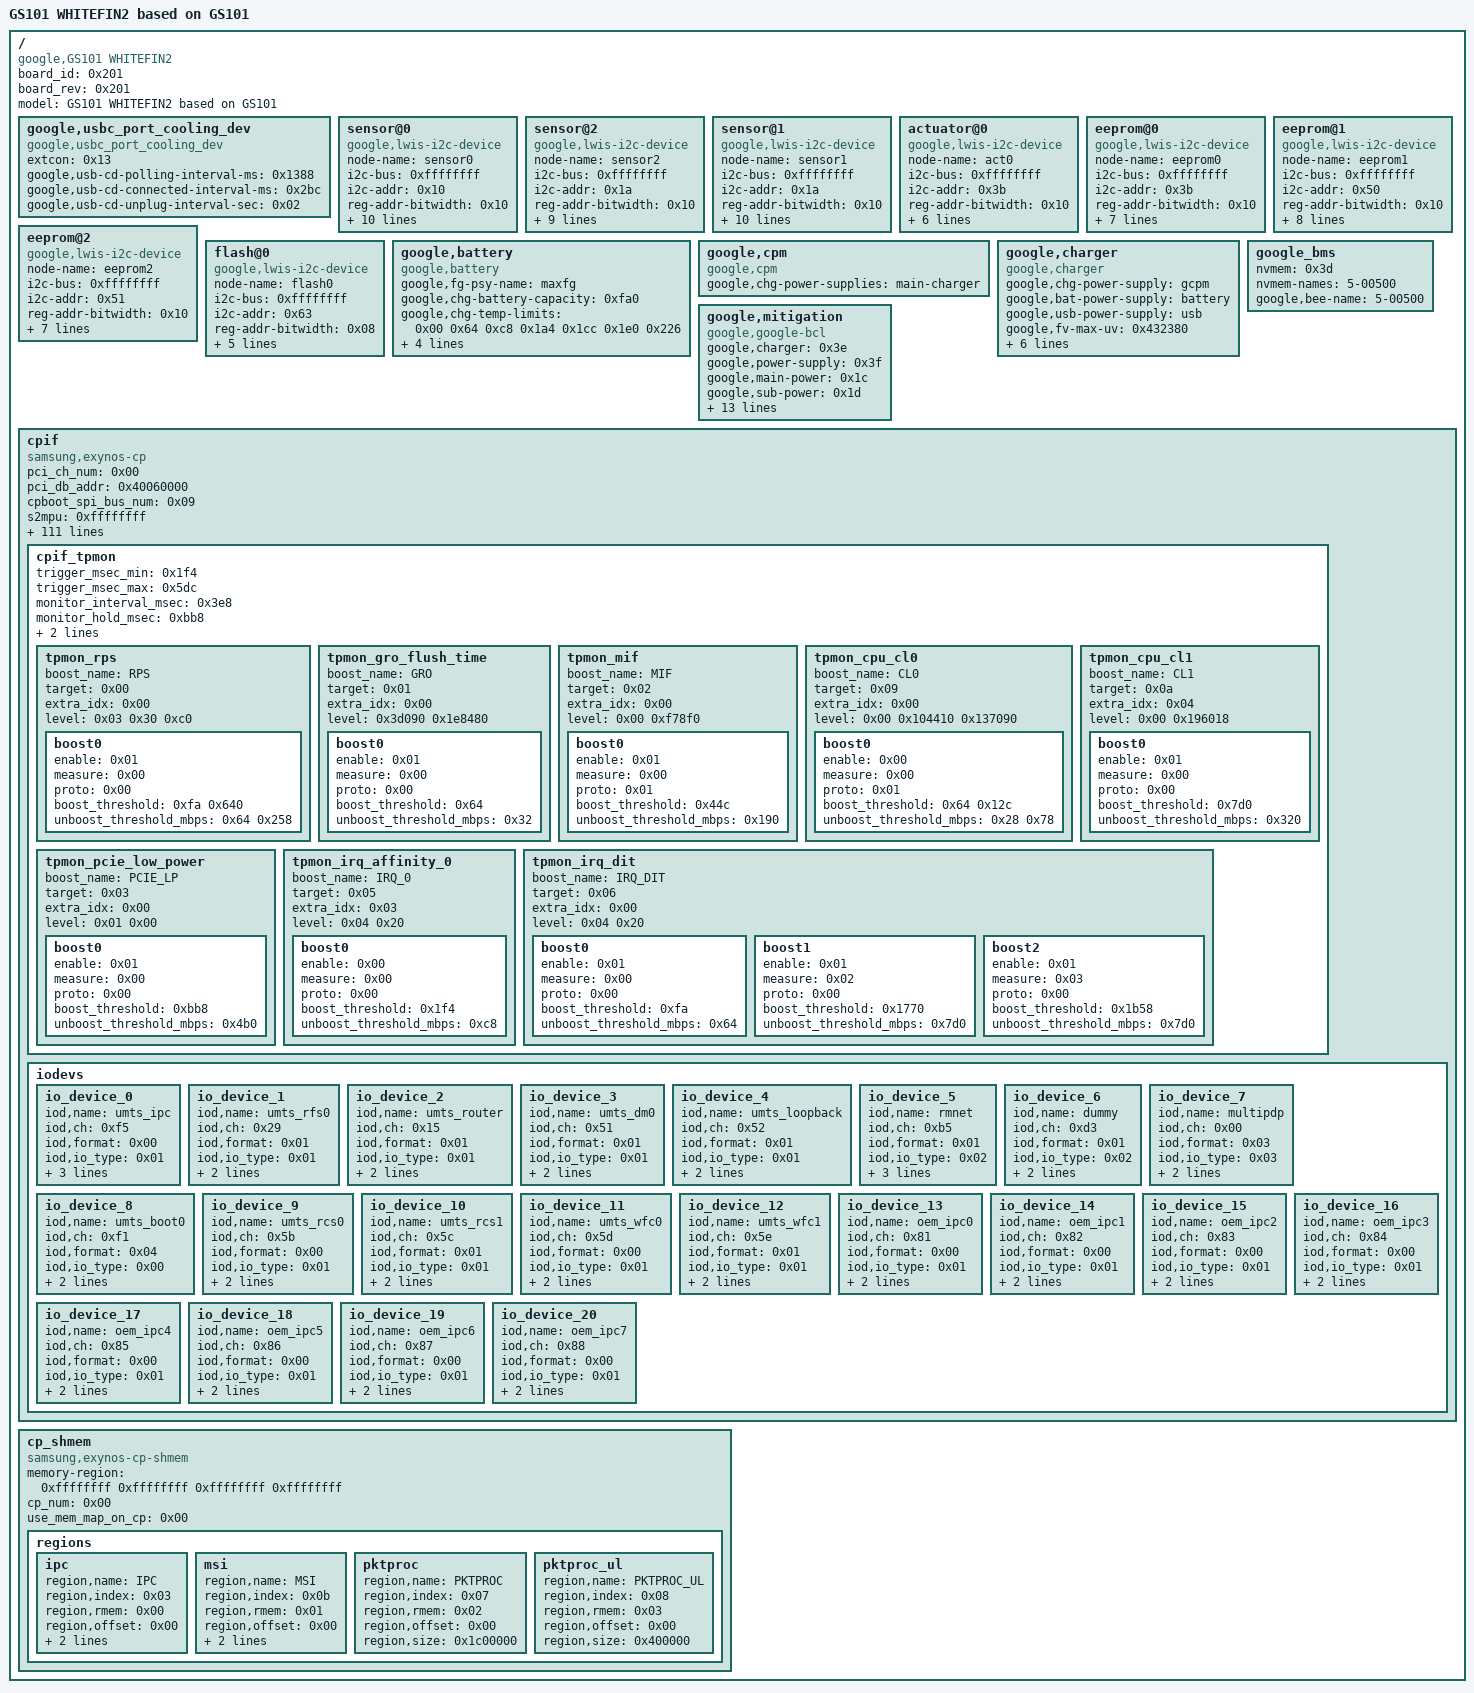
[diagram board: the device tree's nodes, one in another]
/dts-v1/;

/ {
	board_id = <0x201>;
	board_rev = <0x201>;

	fragment@0 {
		target = <0xffffffff>;

		__overlay__ {

			bt-reg-on {
				samsung,pins = "gpp16-2";
				samsung,pin-function = <0x01>;
				samsung,pin-pud = <0x00>;
				samsung,pin-drv = <0x00>;
				samsung,pin-con-pdn = <0x03>;
				samsung,pin-pud-pdn = <0x00>;
				phandle = <0x01>;
			};

			bt-dev-wake {
				samsung,pins = "gpp14-3";
				samsung,pin-function = <0x01>;
				samsung,pin-pud = <0x00>;
				samsung,pin-drv = <0x00>;
				samsung,pin-con-pdn = <0x03>;
				samsung,pin-pud-pdn = <0x01>;
				phandle = <0x02>;
			};
		};
	};

	fragment@1 {
		target = <0xffffffff>;

		__overlay__ {

			bt-host-wake {
				samsung,pins = "gpa6-6";
				samsung,pin-function = <0x0f>;
				samsung,pin-pud = <0x01>;
				samsung,pin-drv = <0x00>;
				samsung,pin-con-pdn = <0x03>;
				samsung,pin-pud-pdn = <0x01>;
				phandle = <0x03>;
			};
		};
	};

	fragment@2 {
		target = <0xffffffff>;

		__overlay__ {
			status = "okay";
		};
	};

	fragment@3 {
		target = <0xffffffff>;

		__overlay__ {

			btbcm {
				compatible = "goog,nitrous";
				pinctrl-0 = <0x01 0x02 0x03>;
				pinctrl-names = "default";
				shutdown-gpios = <0xffffffff 0x02 0x00>;
				host-wakeup-gpios = <0xffffffff 0x06 0x00>;
				device-wakeup-gpios = <0xffffffff 0x03 0x00>;
				status = "okay";
				phandle = <0x67>;
			};
		};
	};

	fragment@4 {
		target = <0xffffffff>;

		__overlay__ {
			#address-cells = <0x01>;
			#size-cells = <0x00>;
			status = "okay";
			pinctrl-names = "default";
			pinctrl-0 = <0xffffffff 0xffffffff>;
			swap-mode = <0x01>;

			bcm4775@0 {
				compatible = "ssp,bcm4775";
				reg = <0x00>;
				spi-max-frequency = <0x18cba80>;
				spi-cpol;
				spi-cpha;
				pinctrl-names = "default";
				pinctrl-0 = <0x04 0x05 0x06 0x07>;
				mcu-req-gpios = <0xffffffff 0x01 0x00>;
				nstandby-gpios = <0xffffffff 0x02 0x01>;

				controller-data {
					samsung,spi-feedback-delay = <0x01>;
					samsung,spi-chip-select-mode = <0x00>;
				};
			};
		};
	};

	fragment@5 {
		target = <0xffffffff>;

		__overlay__ {

			gps-mcu-req {
				samsung,pins = "gpp1-1";
				samsung,pin-function = <0x01>;
				samsung,pin-pud = <0x00>;
				samsung,pin-con-pdn = <0x03>;
				samsung,pin-pud-pdn = <0x00>;
				phandle = <0x05>;
			};

			gps-nstandby {
				samsung,pins = "gpp0-2";
				samsung,pin-function = <0x01>;
				samsung,pin-pud = <0x00>;
				samsung,pin-con-pdn = <0x03>;
				samsung,pin-pud-pdn = <0x00>;
				phandle = <0x07>;
			};
		};
	};

	fragment@6 {
		target = <0xffffffff>;

		__overlay__ {
			#address-cells = <0x01>;
			#size-cells = <0x00>;
			status = "okay";

			fusb307b@50 {
				status = "disabled";
				compatible = "fusb307b";
				reg = <0x50>;
				pinctrl-names = "default";
				pinctrl-0 = <0x08>;
				interrupt-parent = <0xffffffff>;
				usbpd,usbpd_int = <0xffffffff 0x02 0x01>;
				usb-psy-name = "usb";
				chg-psy-name = "gcpm";
				no-bc-12;
				ls = <0x09>;
				conn = <0x0a>;
				orientation-switch;
				phandle = <0x68>;

				connector {
					compatible = "usb-c-connector";
					label = "USB-C";
					data-role = "dual";
					power-role = "dual";
					try-power-role = "sink";
					self-powered;
					op-sink-microwatt = <0x27ac40>;
					usb-role-switch;
					source-pdos = <0x3601905a>;
					sink-pdos = <0x2601912c 0x2d0c8>;
					phandle = <0x0a>;

					port {
						#address-cells = <0x01>;
						#size-cells = <0x00>;

						endpoint@0 {
							reg = <0x00>;
							remote-endpoint = <0x0b>;
							phandle = <0x0c>;
						};
					};
				};

				port {
					#address-cells = <0x01>;
					#size-cells = <0x00>;

					endpoint@0 {
						reg = <0x00>;
						remote-endpoint = <0x0c>;
						phandle = <0x0b>;
					};
				};
			};

			slg46826@8 {
				status = "disabled";
				compatible = "slg46826";
				reg = <0x08>;
				phandle = <0x09>;
			};

			max20339ovp@35 {
				status = "okay";
				compatible = "max20339ovp";
				reg = <0x35>;
				max20339,irq-gpio = <0x0d 0x05 0x01>;
				phandle = <0x0f>;

				max20339_gpio {
					gpio-controller;
					#gpio-cells = <0x02>;
					ngpios = <0x08>;
					phandle = <0x0e>;
				};
			};

			max77759tcpc@25 {
				status = "okay";
				compatible = "max77759tcpc";
				reg = <0x25>;
				pinctrl-names = "default";
				pinctrl-0 = <0x08>;
				interrupt-parent = <0xffffffff>;
				usbpd,usbpd_int = <0xffffffff 0x02 0x01>;
				usb-psy-name = "usb";
				chg-psy-name = "gcpm";
				in-switch-gpio = <0x0e 0x04 0x00>;
				max20339,ovp = <0x0f>;
				conn = <0x10>;
				orientation-switch;
				phandle = <0x13>;

				connector {
					compatible = "usb-c-connector";
					label = "USB-C";
					data-role = "dual";
					power-role = "dual";
					try-power-role = "sink";
					self-powered;
					op-sink-microwatt = <0x27ac40>;
					new-source-frs-typec-current = <0x02>;
					usb-role-switch;
					slow-charger-loop;
					source-pdos = <0x3601905a>;
					sink-pdos = <0x3601912c 0x2d0dc 0xc0dc323c>;
					sink-vdos = <0xd14018d1 0x00 0x4ee10000 0x45800001 0x00 0x23800000>;
					sink-vdos-v1 = <0xd00018d1 0x00 0x4ee10000>;
					phandle = <0x10>;

					port {
						#address-cells = <0x01>;
						#size-cells = <0x00>;

						endpoint@0 {
							reg = <0x00>;
							remote-endpoint = <0x11>;
							phandle = <0x12>;
						};
					};
				};

				port {
					#address-cells = <0x01>;
					#size-cells = <0x00>;

					endpoint@0 {
						reg = <0x00>;
						remote-endpoint = <0x12>;
						phandle = <0x11>;
					};
				};

				max77759_tcpc_gpio {
					gpio-controller;
					#gpio-cells = <0x02>;
					ngpios = <0x01>;
					phandle = <0x57>;
				};
			};
		};
	};

	fragment@7 {
		target = <0xffffffff>;

		__overlay__ {
			samsung,pins = "gpp23-4\0gpp23-5";
			samsung,pin-pud = <0x03>;
		};
	};

	fragment@8 {
		target = <0xffffffff>;

		__overlay__ {

			usb-pd-irq {
				samsung,pins = "gpa8-2";
				samsung,pin-function = <0x0f>;
				samsung,pin-pud = <0x03>;
				samsung,pin-drv = <0x00>;
				phandle = <0x08>;
			};
		};
	};

	fragment@typec {
		target-path = "/";

		__overlay__ {

			google,usbc_port_cooling_dev {
				extcon = <0x13>;
				compatible = "google,usbc_port_cooling_dev";
				google,usb-cd-polling-interval-ms = <0x1388>;
				google,usb-cd-connected-interval-ms = <0x2bc>;
				google,usb-cd-unplug-interval-sec = <0x02>;
				#cooling-cells = <0x02>;
			};
		};
	};

	fragment@9 {
		target = <0xffffffff>;

		__overlay__ {

			cfg_wlanen {
				samsung,pins = "gpp14-2";
				samsung,pin-function = <0x01>;
				samsung,pin-pud = <0x00>;
				samsung,pin-drv = <0x00>;
				samsung,pin-con-pdn = <0x03>;
				samsung,pin-pud-pdn = <0x03>;
				phandle = <0x14>;
			};
		};
	};

	fragment@10 {
		target = <0xffffffff>;

		__overlay__ {

			wlan_host_wake {
				samsung,pins = "gpa7-0";
				samsung,pin-function = <0x0f>;
				samsung,pin-pud = <0x01>;
				samsung,pin-drv = <0x00>;
				samsung,pin-con-pdn = <0x03>;
				samsung,pin-pud-pdn = <0x01>;
				phandle = <0x15>;
			};
		};
	};

	fragment@11 {
		target = <0xffffffff>;

		__overlay__ {

			wlan_dev_wake {
				samsung,pins = "gph2-5";
				samsung,pin-function = <0x00>;
				samsung,pin-pud = <0x01>;
				samsung,pin-drv = <0x00>;
				samsung,pin-con-pdn = <0x03>;
				samsung,pin-pud-pdn = <0x01>;
				phandle = <0x16>;
			};
		};
	};

	fragment@12 {
		target = <0xffffffff>;

		__overlay__ {
			pinctrl-0 = <0xffffffff 0xffffffff 0x14 0x15 0x16>;

			wlan {
				compatible = "android,bcmdhd_wlan";
				wl_reg_on = <0xffffffff 0x02 0x01>;
				wl_host_wake = <0xffffffff 0x00 0x01>;
				wl_dev_wake = <0xffffffff 0x05 0x01>;
				ch-num = <0x01>;
				status = "okay";
			};
		};
	};

	fragment@13 {
		target = <0xffffffff>;

		__overlay__ {

			m-pmic-irq {
				samsung,pins = "gpa0-6";
				samsung,pin-pud = <0x00>;
				phandle = <0x17>;
			};

			s-pmic-irq {
				samsung,pins = "gpa0-7";
				samsung,pin-pud = <0x00>;
				phandle = <0x1a>;
			};

			smpl-warn {
				samsung,pins = "gpa5-0";
				samsung,pin-function = <0x0f>;
				samsung,pin-pud = <0x00>;
				samsung,pin-drv = <0x00>;
				phandle = <0x18>;
			};
		};
	};

	fragment@14 {
		target = <0xffffffff>;

		__overlay__ {
			#address-cells = <0x01>;
			#size-cells = <0x00>;
			status = "okay";

			s2mpg10mfd@00 {
				compatible = "samsung,s2mpg10mfd";
				acpm-ipc-channel = <0x02>;
				acpm-speedy-channel = <0x00>;
				s2mpg10,wakeup = "enabled";
				s2mpg10,irq-gpio = <0xffffffff 0x06 0x00>;
				reg = <0x1f>;
				interrupts = <0x01 0x00 0x00 0x01 0x00 0x01 0x01 0x00 0x02 0x01 0x00 0x03 0x01 0x00 0x04 0x01 0x00 0x05 0x01 0x00 0x06>;
				interrupt-parent = <0xffffffff>;
				pinctrl-names = "default";
				pinctrl-0 = <0x17 0x18>;
				gpios = <0xffffffff 0x00 0x00 0xffffffff 0x01 0x00 0xffffffff 0x02 0x00 0xffffffff 0x03 0x00 0xffffffff 0x04 0x00 0xffffffff 0x01 0x00 0xffffffff 0x03 0x00>;
				#thermal-sensor-cells = <0x01>;
				smpl_warn_en = <0x01>;
				smpl_warn_vth = <0x03>;
				smpl_warn_hys = <0x01>;
				b2_ocp_warn_en = <0x01>;
				b2_ocp_warn_cnt = <0x00>;
				b2_ocp_warn_dvs_mask = <0x00>;
				b2_ocp_warn_lvl = <0x08>;
				b3_ocp_warn_en = <0x01>;
				b3_ocp_warn_cnt = <0x00>;
				b3_ocp_warn_dvs_mask = <0x00>;
				b3_ocp_warn_lvl = <0x0d>;
				b10_ocp_warn_en = <0x01>;
				b10_ocp_warn_cnt = <0x00>;
				b10_ocp_warn_dvs_mask = <0x00>;
				b10_ocp_warn_lvl = <0x0d>;
				b2_soft_ocp_warn_en = <0x01>;
				b2_soft_ocp_warn_cnt = <0x00>;
				b2_soft_ocp_warn_dvs_mask = <0x00>;
				b2_soft_ocp_warn_lvl = <0x08>;
				b3_soft_ocp_warn_en = <0x01>;
				b3_soft_ocp_warn_cnt = <0x00>;
				b3_soft_ocp_warn_dvs_mask = <0x00>;
				b3_soft_ocp_warn_lvl = <0x0d>;
				b10_soft_ocp_warn_en = <0x01>;
				b10_soft_ocp_warn_cnt = <0x00>;
				b10_soft_ocp_warn_dvs_mask = <0x00>;
				b10_soft_ocp_warn_lvl = <0x14>;
				buck_ocp_ctrl1 = <0xbb>;
				buck_ocp_ctrl2 = <0xbb>;
				buck_ocp_ctrl3 = <0xbb>;
				buck_ocp_ctrl4 = <0xbb>;
				buck_ocp_ctrl5 = <0xbb>;
				wtsr_en = "enabled";
				coldrst_en = "disabled";
				smpl_en = "disabled";
				wtsr_timer_val = <0x03>;
				coldrst_timer_val = <0x03>;
				smpl_timer_val = <0x04>;
				sub_smpl_en = "disabled";
				check_jigon = <0x00>;
				init_time,sec = <0x00>;
				init_time,min = <0x00>;
				init_time,hour = <0x0c>;
				init_time,mday = <0x01>;
				init_time,mon = <0x00>;
				init_time,year = <0x78>;
				init_time,wday = <0x03>;
				phandle = <0x1c>;

				regulators {

					BUCK1M {
						regulator-name = "S2MPG10_BUCK1";
						regulator-min-microvolt = <0x6ddd0>;
						regulator-max-microvolt = <0x13d620>;
						regulator-always-on;
						regulator-initial-mode = <0x01>;
						channel-mux-selection = <0x01>;
						schematic-name = "S1M_VDD_MIF";
						subsys-name = "MIF";
						buck_rail;
						channel-en-byte-offset = <0x00>;
						channel-en-index = <0x01>;
						phandle = <0x69>;
					};

					BUCK2M {
						regulator-name = "S2MPG10_BUCK2";
						regulator-min-microvolt = <0x6ddd0>;
						regulator-max-microvolt = <0x13d620>;
						regulator-always-on;
						regulator-initial-mode = <0x01>;
						channel-mux-selection = <0x02>;
						schematic-name = "S2M_VDD_CPUCL2";
						subsys-name = "CPU(BIG)";
						buck_rail;
						channel-en-byte-offset = <0x00>;
						channel-en-index = <0x02>;
						odpm_disable_in_sleep;
						phandle = <0x6a>;
					};

					BUCK3M {
						regulator-name = "S2MPG10_BUCK3";
						regulator-min-microvolt = <0x6ddd0>;
						regulator-max-microvolt = <0x13d620>;
						regulator-always-on;
						regulator-initial-mode = <0x01>;
						channel-mux-selection = <0x03>;
						schematic-name = "S3M_VDD_CPUCL1";
						subsys-name = "CPU(MID)";
						buck_rail;
						channel-en-byte-offset = <0x00>;
						channel-en-index = <0x04>;
						odpm_disable_in_sleep;
						phandle = <0x6b>;
					};

					BUCK4M {
						regulator-name = "S2MPG10_BUCK4";
						regulator-min-microvolt = <0x6ddd0>;
						regulator-max-microvolt = <0x13d620>;
						regulator-always-on;
						regulator-initial-mode = <0x01>;
						channel-mux-selection = <0x04>;
						schematic-name = "S4M_VDD_CPUCL0";
						subsys-name = "CPU(LITTLE)";
						buck_rail;
						channel-en-byte-offset = <0x00>;
						channel-en-index = <0x08>;
						odpm_disable_in_sleep;
						phandle = <0x6c>;
					};

					BUCK5M {
						regulator-name = "S2MPG10_BUCK5";
						regulator-min-microvolt = <0x6ddd0>;
						regulator-max-microvolt = <0x13d620>;
						regulator-always-on;
						regulator-initial-mode = <0x01>;
						channel-mux-selection = <0x05>;
						schematic-name = "S5M_VDD_INT";
						subsys-name = "INT";
						buck_rail;
						channel-en-byte-offset = <0x00>;
						channel-en-index = <0x10>;
						odpm_disable_in_sleep;
						phandle = <0x6d>;
					};

					BUCK6M {
						regulator-name = "S2MPG10_BUCK6";
						regulator-min-microvolt = <0x6ddd0>;
						regulator-max-microvolt = <0x13d620>;
						regulator-always-on;
						regulator-initial-mode = <0x01>;
						channel-mux-selection = <0x06>;
						schematic-name = "S6M_VDD_CPUCL2_M";
						subsys-name = "CPU(BIG)";
						buck_rail;
						channel-en-byte-offset = <0x00>;
						channel-en-index = <0x20>;
						odpm_disable_in_sleep;
						phandle = <0x6e>;
					};

					BUCK7M {
						regulator-name = "S2MPG10_BUCK7";
						regulator-min-microvolt = <0x6ddd0>;
						regulator-max-microvolt = <0x13d620>;
						regulator-always-on;
						regulator-initial-mode = <0x01>;
						channel-mux-selection = <0x07>;
						schematic-name = "S7M_VDD_INT_M";
						subsys-name = "INT";
						buck_rail;
						channel-en-byte-offset = <0x00>;
						channel-en-index = <0x40>;
						odpm_disable_in_sleep;
						phandle = <0x6f>;
					};

					BUCK8M {
						regulator-name = "S2MPG10_BUCK8";
						regulator-min-microvolt = <0x6ddd0>;
						regulator-max-microvolt = <0x13d620>;
						regulator-always-on;
						regulator-initial-mode = <0x03>;
						channel-mux-selection = <0x08>;
						schematic-name = "S8M_LLDO2";
						subsys-name = "LDO";
						buck_rail;
						channel-en-byte-offset = <0x00>;
						channel-en-index = <0x80>;
						phandle = <0x70>;
					};

					BUCK9M {
						regulator-name = "S2MPG10_BUCK9";
						regulator-min-microvolt = <0x6ddd0>;
						regulator-max-microvolt = <0x13d620>;
						regulator-always-on;
						regulator-initial-mode = <0x03>;
						channel-mux-selection = <0x09>;
						schematic-name = "S9M_LLDO3";
						subsys-name = "LDO";
						buck_rail;
						channel-en-byte-offset = <0x01>;
						channel-en-index = <0x01>;
						phandle = <0x71>;
					};

					BUCK10M {
						regulator-name = "S2MPG10_BUCK10";
						regulator-min-microvolt = <0x6ddd0>;
						regulator-max-microvolt = <0x13d620>;
						regulator-always-on;
						regulator-initial-mode = <0x01>;
						channel-mux-selection = <0x0a>;
						schematic-name = "S10M_VDD_TPU";
						subsys-name = "TPU";
						buck_rail;
						channel-en-byte-offset = <0x01>;
						channel-en-index = <0x02>;
						odpm_disable_in_sleep;
						phandle = <0x72>;
					};

					LDO1M {
						regulator-name = "S2MPG10_LDO1";
						regulator-min-microvolt = <0xaae60>;
						regulator-max-microvolt = <0x13d620>;
						regulator-always-on;
						regulator-initial-mode = <0x03>;
						channel-mux-selection = <0x21>;
						schematic-name = "L1M_ALIVE";
						subsys-name = "Alive";
						phandle = <0x73>;
					};

					LDO2M {
						regulator-name = "S2MPG10_LDO2";
						regulator-min-microvolt = <0x186a00>;
						regulator-max-microvolt = <0x1dc130>;
						regulator-always-on;
						regulator-initial-mode = <0x03>;
						channel-mux-selection = <0x22>;
						schematic-name = "L2M_ALIVE";
						subsys-name = "DDR";
						phandle = <0x74>;
					};

					LDO3M {
						regulator-name = "S2MPG10_LDO3";
						regulator-min-microvolt = <0xb1008>;
						regulator-max-microvolt = <0x13d620>;
						regulator-always-on;
						regulator-initial-mode = <0x01>;
						channel-mux-selection = <0x23>;
						schematic-name = "L3M";
						subsys-name = "IO";
						phandle = <0x75>;
					};

					LDO4M {
						regulator-name = "S2MPG10_LDO4";
						regulator-min-microvolt = <0x186a00>;
						regulator-max-microvolt = <0x1dc130>;
						regulator-always-on;
						regulator-initial-mode = <0x01>;
						channel-mux-selection = <0x24>;
						schematic-name = "L4M";
						subsys-name = "IO";
						phandle = <0x76>;
					};

					LDO5M {
						regulator-name = "S2MPG10_LDO5";
						regulator-min-microvolt = <0xb1008>;
						regulator-max-microvolt = <0x13d620>;
						regulator-always-on;
						regulator-initial-mode = <0x01>;
						channel-mux-selection = <0x25>;
						schematic-name = "L5M_TCXO";
						subsys-name = "PLL";
						phandle = <0x77>;
					};

					LDO6M {
						regulator-name = "S2MPG10_LDO6";
						regulator-min-microvolt = <0xb1008>;
						regulator-max-microvolt = <0x13d620>;
						regulator-always-on;
						regulator-initial-mode = <0x01>;
						channel-mux-selection = <0x26>;
						schematic-name = "L6M_PLL";
						subsys-name = "PLL";
						phandle = <0x78>;
					};

					LDO7M {
						regulator-name = "S2MPG10_LDO7";
						regulator-min-microvolt = <0x6ddd0>;
						regulator-max-microvolt = <0xe7ef0>;
						regulator-initial-mode = <0x03>;
						channel-mux-selection = <0x27>;
						schematic-name = "L7M_VDD_HSI";
						subsys-name = "IO";
						phandle = <0x23>;
					};

					LDO8M {
						regulator-name = "S2MPG10_LDO8";
						regulator-min-microvolt = <0xb1008>;
						regulator-max-microvolt = <0x13d620>;
						regulator-initial-mode = <0x03>;
						channel-mux-selection = <0x28>;
						schematic-name = "L8M_USB";
						subsys-name = "USB";
						phandle = <0x24>;
					};

					LDO9M {
						regulator-name = "S2MPG10_LDO9";
						regulator-min-microvolt = <0x186a00>;
						regulator-max-microvolt = <0x1dc130>;
						regulator-initial-mode = <0x03>;
						channel-mux-selection = <0x29>;
						schematic-name = "L9M_USB";
						subsys-name = "USB";
						phandle = <0x25>;
					};

					LDO10M {
						regulator-name = "S2MPG10_LDO10";
						regulator-min-microvolt = <0x1b7740>;
						regulator-max-microvolt = <0x331df0>;
						regulator-initial-mode = <0x03>;
						channel-mux-selection = <0x2a>;
						schematic-name = "L10M_USB";
						subsys-name = "USB";
						phandle = <0x26>;
					};

					LDO11M {
						regulator-name = "S2MPG10_LDO11";
						regulator-min-microvolt = <0xaae60>;
						regulator-max-microvolt = <0x13d620>;
						regulator-always-on;
						regulator-initial-mode = <0x01>;
						channel-mux-selection = <0x2b>;
						schematic-name = "L11M_VDD_CPUCL1_M";
						subsys-name = "CPU(MID)";
						phandle = <0x79>;
					};

					LDO12M {
						regulator-name = "S2MPG10_LDO12";
						regulator-min-microvolt = <0xaae60>;
						regulator-max-microvolt = <0x13d620>;
						regulator-always-on;
						regulator-initial-mode = <0x01>;
						channel-mux-selection = <0x2c>;
						schematic-name = "L12M_VDD_CPUCL0_M";
						subsys-name = "CPU(LITTLE)";
						phandle = <0x7a>;
					};

					LDO13M {
						regulator-name = "S2MPG10_LDO13";
						regulator-min-microvolt = <0x6ddd0>;
						regulator-max-microvolt = <0xe7ef0>;
						regulator-always-on;
						regulator-initial-mode = <0x01>;
						channel-mux-selection = <0x2d>;
						schematic-name = "L13M_VDD_TPU_M";
						subsys-name = "TPU";
						phandle = <0x7b>;
					};

					LDO14M {
						regulator-name = "S2MPG10_LDO14";
						regulator-min-microvolt = <0x186a00>;
						regulator-max-microvolt = <0x1dc130>;
						regulator-initial-mode = <0x01>;
						regulator-always-on;
						channel-mux-selection = <0x2e>;
						schematic-name = "L14M_AVDD_TCXO";
						subsys-name = "PLL";
						phandle = <0x7c>;
					};

					LDO15M {
						regulator-name = "S2MPG10_LDO15";
						regulator-min-microvolt = <0x6ddd0>;
						regulator-max-microvolt = <0xe7ef0>;
						regulator-always-on;
						regulator-initial-mode = <0x03>;
						channel-mux-selection = <0x2f>;
						schematic-name = "L15M_VDD_SLC_M";
						subsys-name = "SLC";
						phandle = <0x7d>;
					};

					LDO16M {
						regulator-name = "S2MPG10_LDO16";
						regulator-min-microvolt = <0xb1008>;
						regulator-max-microvolt = <0x13d620>;
						regulator-always-on;
						regulator-initial-mode = <0x01>;
						channel-mux-selection = <0x30>;
						schematic-name = "L16M_PCIE0";
						subsys-name = "PCIE";
						phandle = <0x27>;
					};

					LDO17M {
						regulator-name = "S2MPG10_LDO17";
						regulator-min-microvolt = <0xb1008>;
						regulator-max-microvolt = <0x13d620>;
						regulator-always-on;
						regulator-initial-mode = <0x01>;
						channel-mux-selection = <0x31>;
						schematic-name = "L17M_PCIE1";
						subsys-name = "PCIE";
						phandle = <0x29>;
					};

					LDO18M {
						regulator-name = "S2MPG10_LDO18";
						regulator-min-microvolt = <0x186a00>;
						regulator-max-microvolt = <0x1dc130>;
						regulator-always-on;
						regulator-initial-mode = <0x01>;
						channel-mux-selection = <0x32>;
						schematic-name = "L18M_PCIE0";
						subsys-name = "PCIE";
						phandle = <0x28>;
					};

					LDO19M {
						regulator-name = "S2MPG10_LDO19";
						regulator-min-microvolt = <0x186a00>;
						regulator-max-microvolt = <0x1dc130>;
						regulator-always-on;
						regulator-initial-mode = <0x01>;
						channel-mux-selection = <0x33>;
						schematic-name = "L19M_PCIE1";
						subsys-name = "PCIE";
						phandle = <0x2a>;
					};

					LDO20M {
						regulator-name = "S2MPG10_LDO20";
						regulator-min-microvolt = <0x186a00>;
						regulator-max-microvolt = <0x1dc130>;
						regulator-always-on;
						regulator-initial-mode = <0x01>;
						channel-mux-selection = <0x34>;
						schematic-name = "L20M_DMICS";
						subsys-name = "DMIC";
						phandle = <0x7e>;
					};

					LDO21M {
						regulator-name = "S2MPG10_LDO21";
						regulator-min-microvolt = <0x2625a0>;
						regulator-max-microvolt = <0x325aa0>;
						regulator-always-on;
						regulator-initial-mode = <0x03>;
						channel-mux-selection = <0x35>;
						schematic-name = "L21M_DTLS";
						subsys-name = "DTLS";
						phandle = <0x7f>;
					};

					LDO22M {
						regulator-name = "S2MPG10_LDO22";
						regulator-min-microvolt = <0x2625a0>;
						regulator-max-microvolt = <0x325aa0>;
						regulator-initial-mode = <0x03>;
						channel-mux-selection = <0x36>;
						schematic-name = "L22M_DISP_VCI";
						subsys-name = "Display";
						phandle = <0x49>;
					};

					LDO23M {
						regulator-name = "S2MPG10_LDO23";
						regulator-min-microvolt = <0x186a00>;
						regulator-max-microvolt = <0x1dc130>;
						regulator-initial-mode = <0x03>;
						channel-mux-selection = <0x37>;
						schematic-name = "L23M_DISP_VDDI";
						subsys-name = "Display";
						regulator-always-on;
						phandle = <0x80>;
					};

					LDO24M {
						regulator-name = "S2MPG10_LDO24";
						regulator-min-microvolt = <0xb1008>;
						regulator-max-microvolt = <0x13d620>;
						channel-mux-selection = <0x38>;
						schematic-name = "L24M_UNUSED";
						subsys-name = "Spare";
						phandle = <0x81>;
					};

					LDO25M {
						regulator-name = "S2MPG10_LDO25";
						regulator-min-microvolt = <0x186a00>;
						regulator-max-microvolt = <0x1dc130>;
						regulator-initial-mode = <0x03>;
						channel-mux-selection = <0x39>;
						schematic-name = "L25M_TSP_DVDD";
						subsys-name = "Touch";
						phandle = <0x52>;
					};

					LDO26M {
						regulator-name = "S2MPG10_LDO26";
						regulator-min-microvolt = <0x2625a0>;
						regulator-max-microvolt = <0x325aa0>;
						regulator-initial-mode = <0x03>;
						channel-mux-selection = <0x3a>;
						schematic-name = "L26M_TS_AVDD";
						subsys-name = "Touch";
						phandle = <0x53>;
					};

					LDO27M {
						regulator-name = "S2MPG10_LDO27";
						regulator-min-microvolt = <0x2625a0>;
						regulator-max-microvolt = <0x325aa0>;
						regulator-initial-mode = <0x03>;
						channel-mux-selection = <0x3b>;
						schematic-name = "L27M_UDFPS_AVDD";
						subsys-name = "UDFPS";
						phandle = <0x82>;
					};

					LDO28M {
						regulator-name = "S2MPG10_LDO28";
						regulator-min-microvolt = <0xb1008>;
						regulator-max-microvolt = <0x13d620>;
						regulator-initial-mode = <0x03>;
						channel-mux-selection = <0x3c>;
						schematic-name = "L28M_DISP_VDDD";
						subsys-name = "Display";
						phandle = <0x83>;
					};

					LDO29M {
						regulator-name = "S2MPG10_LDO29";
						regulator-min-microvolt = <0x186a00>;
						regulator-max-microvolt = <0x1dc130>;
						channel-mux-selection = <0x3d>;
						schematic-name = "L29M_UNUSED";
						subsys-name = "Spare";
						phandle = <0x84>;
					};

					LDO30M {
						regulator-name = "S2MPG10_LDO30";
						regulator-min-microvolt = <0x186a00>;
						regulator-max-microvolt = <0x1dc130>;
						channel-mux-selection = <0x3e>;
						schematic-name = "L30M_DMICS";
						subsys-name = "Spare";
						regulator-always-on;
						phandle = <0x85>;
					};

					LDO31M {
						regulator-name = "S2MPG10_LDO31";
						regulator-min-microvolt = <0x186a00>;
						regulator-max-microvolt = <0x1dc130>;
						regulator-initial-mode = <0x03>;
						channel-mux-selection = <0x3f>;
						schematic-name = "L31M_DISP_VDDI";
						subsys-name = "NFC";
						regulator-always-on;
						phandle = <0x4a>;
					};
				};

				odpm {
					chip-name = "S2MPG10";
					sample-rate-uhz = <0x7735940>;
					sample-rate-external-uhz = <0x1d19574>;
					max-refresh-time-ms = <0xdbba0>;

					channels {

						channel@0 {
							rail-name = "BUCK10M";
							channel_enabled;
							phandle = <0x86>;
						};

						channel@1 {
							rail-name = "VSEN_C2";
							channel_enabled;
							phandle = <0x87>;
						};

						channel@2 {
							rail-name = "VSEN_C3";
							channel_enabled;
							phandle = <0x88>;
						};

						channel@3 {
							rail-name = "BUCK2M";
							channel_enabled;
							phandle = <0x89>;
						};

						channel@4 {
							rail-name = "BUCK3M";
							channel_enabled;
							phandle = <0x8a>;
						};

						channel@5 {
							rail-name = "BUCK4M";
							channel_enabled;
							phandle = <0x8b>;
						};

						channel@6 {
							rail-name = "BUCK5M";
							channel_enabled;
							phandle = <0x8c>;
						};

						channel@7 {
							rail-name = "BUCK1M";
							channel_enabled;
							phandle = <0x8d>;
						};
					};

					rails {
						use-regulators-as-rails;

						VSEN_C1 {
							external_rail;
							channel-en-index = <0x01>;
							channel-mux-selection = <0x5c>;
							shunt-res-uohms = <0x2710>;
							schematic-name = "VSEN_C1_NC";
							subsys-name = "Spare";
							phandle = <0x8e>;
						};

						VSEN_C2 {
							external_rail;
							channel-en-index = <0x02>;
							channel-mux-selection = <0x5d>;
							shunt-res-uohms = <0x1388>;
							schematic-name = "VSYS_PWR_MODEM";
							subsys-name = "Modem";
							phandle = <0x8f>;
						};

						VSEN_C3 {
							external_rail;
							channel-en-index = <0x04>;
							channel-mux-selection = <0x5e>;
							shunt-res-uohms = <0x1388>;
							schematic-name = "VSYS_PWR_RFFE";
							subsys-name = "Cellular";
							phandle = <0x90>;
						};
					};
				};

				s2mpg10_gpio {
					gpio-controller;
					#gpio-cells = <0x02>;
					ngpios = <0x06>;
					gpio-ranges = <0x19 0x00 0x00 0x06>;
					phandle = <0x91>;
				};

				s2mpg10_pinctrl {
					phandle = <0x19>;
				};
			};
		};
	};

	fragment@15 {
		target = <0xffffffff>;

		__overlay__ {
			#address-cells = <0x01>;
			#size-cells = <0x00>;
			status = "okay";

			s2mpg11mfd@00 {
				compatible = "samsung,s2mpg11mfd";
				acpm-ipc-channel = <0x02>;
				acpm-speedy-channel = <0x01>;
				s2mpg11,wakeup = "enabled";
				s2mpg11,irq-gpio = <0xffffffff 0x07 0x00>;
				reg = <0x2f>;
				interrupts = <0x01 0x00 0x00 0x01 0x00 0x01>;
				interrupt-parent = <0xffffffff>;
				pinctrl-names = "default";
				pinctrl-0 = <0x1a>;
				gpios = <0xffffffff 0x00 0x00 0xffffffff 0x02 0x00>;
				#thermal-sensor-cells = <0x01>;
				b2_ocp_warn_en = <0x01>;
				b2_ocp_warn_cnt = <0x00>;
				b2_ocp_warn_dvs_mask = <0x00>;
				b2_ocp_warn_lvl = <0x08>;
				b2_soft_ocp_warn_en = <0x01>;
				b2_soft_ocp_warn_cnt = <0x00>;
				b2_soft_ocp_warn_dvs_mask = <0x00>;
				b2_soft_ocp_warn_lvl = <0x08>;
				buck_ocp_ctrl1 = <0xbb>;
				buck_ocp_ctrl2 = <0xbb>;
				buck_ocp_ctrl3 = <0xbb>;
				buck_ocp_ctrl4 = <0xbb>;
				buck_ocp_ctrl5 = <0xbb>;
				buck_ocp_ctrl6 = <0xbb>;
				buck_ocp_ctrl7 = <0x0b>;
				phandle = <0x1d>;

				regulators {

					BUCK1S {
						regulator-name = "S2MPG11_BUCK1";
						regulator-min-microvolt = <0x6ddd0>;
						regulator-max-microvolt = <0x13d620>;
						regulator-always-on;
						regulator-initial-mode = <0x01>;
						channel-mux-selection = <0x01>;
						schematic-name = "S1S_VDD_CAM";
						subsys-name = "Multimedia";
						buck_rail;
						channel-en-byte-offset = <0x00>;
						channel-en-index = <0x01>;
						odpm_disable_in_sleep;
						phandle = <0x92>;
					};

					BUCK2S {
						regulator-name = "S2MPG11_BUCK2";
						regulator-min-microvolt = <0x6ddd0>;
						regulator-max-microvolt = <0x13d620>;
						regulator-always-on;
						regulator-initial-mode = <0x01>;
						channel-mux-selection = <0x02>;
						schematic-name = "S2S_VDD_G3D";
						subsys-name = "GPU";
						buck_rail;
						channel-en-byte-offset = <0x00>;
						channel-en-index = <0x02>;
						odpm_disable_in_sleep;
						phandle = <0x93>;
					};

					BUCK3S {
						regulator-name = "S2MPG11_BUCK3";
						regulator-min-microvolt = <0x6ddd0>;
						regulator-max-microvolt = <0x13d620>;
						regulator-always-on;
						regulator-initial-mode = <0x03>;
						channel-mux-selection = <0x03>;
						schematic-name = "S3S_LLDO1";
						subsys-name = "LDO";
						buck_rail;
						channel-en-byte-offset = <0x00>;
						channel-en-index = <0x04>;
						phandle = <0x94>;
					};

					BUCK4S {
						regulator-name = "S2MPG11_BUCK4";
						regulator-min-microvolt = <0x6ddd0>;
						regulator-max-microvolt = <0x13d620>;
						regulator-always-on;
						regulator-initial-mode = <0x03>;
						channel-mux-selection = <0x04>;
						schematic-name = "S4S_VDD2H_MEM";
						subsys-name = "DDR";
						buck_rail;
						channel-en-byte-offset = <0x00>;
						channel-en-index = <0x08>;
						phandle = <0x95>;
					};

					BUCK5S {
						regulator-name = "S2MPG11_BUCK5";
						regulator-min-microvolt = <0x61a80>;
						regulator-max-microvolt = <0x13d620>;
						regulator-always-on;
						regulator-initial-mode = <0x01>;
						channel-mux-selection = <0x05>;
						schematic-name = "S5S_VDDQ_MEM";
						subsys-name = "DDR";
						buck_rail;
						channel-en-byte-offset = <0x00>;
						channel-en-index = <0x10>;
						phandle = <0x96>;
					};

					BUCK6S {
						regulator-name = "S2MPG11_BUCK6";
						regulator-min-microvolt = <0xf4240>;
						regulator-max-microvolt = <0x16e360>;
						regulator-always-on;
						regulator-initial-mode = <0x03>;
						channel-mux-selection = <0x06>;
						schematic-name = "S6S_LLDO4";
						subsys-name = "LDO";
						buck_rail;
						channel-en-byte-offset = <0x00>;
						channel-en-index = <0x20>;
						phandle = <0x97>;
					};

					BUCK7S {
						regulator-name = "S2MPG11_BUCK7";
						regulator-min-microvolt = <0x16e360>;
						regulator-max-microvolt = <0x2191c0>;
						regulator-always-on;
						regulator-initial-mode = <0x03>;
						channel-mux-selection = <0x07>;
						schematic-name = "S7S_MLDO";
						subsys-name = "LDO";
						buck_rail;
						channel-en-byte-offset = <0x00>;
						channel-en-index = <0x40>;
						phandle = <0x98>;
					};

					BUCK8S {
						regulator-name = "S2MPG11_BUCK8";
						regulator-min-microvolt = <0x6ddd0>;
						regulator-max-microvolt = <0x13d620>;
						regulator-always-on;
						regulator-initial-mode = <0x01>;
						channel-mux-selection = <0x08>;
						schematic-name = "S8S_VDD_G3D_L2";
						subsys-name = "GPU";
						buck_rail;
						channel-en-byte-offset = <0x00>;
						channel-en-index = <0x80>;
						odpm_disable_in_sleep;
						phandle = <0x99>;
					};

					BUCK9S {
						regulator-name = "S2MPG11_BUCK9";
						regulator-min-microvolt = <0x6ddd0>;
						regulator-max-microvolt = <0x13d620>;
						regulator-always-on;
						regulator-initial-mode = <0x03>;
						channel-mux-selection = <0x09>;
						schematic-name = "S9S_VDD_AOC";
						subsys-name = "AOC";
						buck_rail;
						channel-en-byte-offset = <0x01>;
						channel-en-index = <0x01>;
						phandle = <0x9a>;
					};

					BUCK10S {
						regulator-name = "S2MPG11_BUCK10";
						regulator-min-microvolt = <0x6ddd0>;
						regulator-max-microvolt = <0x13d620>;
						regulator-always-on;
						regulator-initial-mode = <0x03>;
						channel-mux-selection = <0x0a>;
						schematic-name = "S10S_VDD2L";
						subsys-name = "DDR";
						buck_rail;
						channel-en-byte-offset = <0x01>;
						channel-en-index = <0x02>;
						phandle = <0x9b>;
					};

					BUCKD {
						regulator-name = "S2MPG11_BUCKD";
						regulator-min-microvolt = <0x249f00>;
						regulator-max-microvolt = <0x325aa0>;
						regulator-always-on;
						regulator-initial-mode = <0x01>;
						channel-mux-selection = <0x0b>;
						schematic-name = "SD";
						subsys-name = "UFS";
						buck_rail;
						channel-en-byte-offset = <0x01>;
						channel-en-index = <0x04>;
						odpm_disable_in_sleep;
						phandle = <0x9c>;
					};

					BUCKA {
						regulator-name = "S2MPG11_BUCKA";
						regulator-min-microvolt = <0x19f0a0>;
						regulator-max-microvolt = <0x200b20>;
						regulator-always-on;
						regulator-initial-mode = <0x03>;
						channel-mux-selection = <0x0c>;
						schematic-name = "SA";
						subsys-name = "IO";
						buck_rail;
						channel-en-byte-offset = <0x01>;
						channel-en-index = <0x08>;
						phandle = <0x64>;
					};

					BUCKBOOST {
						regulator-name = "S2MPG11_BUCKBOOST";
						regulator-min-microvolt = <0x2dc6c0>;
						regulator-max-microvolt = <0x36ee80>;
						regulator-always-on;
						regulator-initial-mode = <0x03>;
						channel-mux-selection = <0x0d>;
						schematic-name = "BB_HLDO";
						subsys-name = "LDO";
						buck_rail;
						channel-en-byte-offset = <0x01>;
						channel-en-index = <0x10>;
						phandle = <0x9d>;
					};

					LDO1S {
						regulator-name = "S2MPG11_LDO1";
						regulator-min-microvolt = <0x6ddd0>;
						regulator-max-microvolt = <0xe7ef0>;
						regulator-always-on;
						regulator-initial-mode = <0x01>;
						channel-mux-selection = <0x21>;
						schematic-name = "L1S_VDD_G3D_M";
						subsys-name = "GPU";
						phandle = <0x9e>;
					};

					LDO2S {
						regulator-name = "S2MPG11_LDO2";
						regulator-min-microvolt = <0x6ddd0>;
						regulator-max-microvolt = <0xe7ef0>;
						regulator-always-on;
						regulator-initial-mode = <0x01>;
						channel-mux-selection = <0x22>;
						schematic-name = "L2S_VDD_AOC_RET";
						subsys-name = "AOC";
						phandle = <0x9f>;
					};

					LDO3S {
						regulator-name = "S2MPG11_LDO3";
						regulator-min-microvolt = <0x186a00>;
						regulator-max-microvolt = <0x1dc130>;
						channel-mux-selection = <0x23>;
						schematic-name = "L3S_UNUSED";
						subsys-name = "Spare";
						phandle = <0xa0>;
					};

					LDO4S {
						regulator-name = "S2MPG11_LDO4";
						regulator-min-microvolt = <0x2625a0>;
						regulator-max-microvolt = <0x325aa0>;
						regulator-initial-mode = <0x03>;
						channel-mux-selection = <0x24>;
						schematic-name = "L4S_UWB";
						subsys-name = "UWB";
						regulator-always-on;
						phandle = <0xa1>;
					};

					LDO5S {
						regulator-name = "S2MPG11_LDO5";
						regulator-min-microvolt = <0x186a00>;
						regulator-max-microvolt = <0x1dc130>;
						channel-mux-selection = <0x25>;
						schematic-name = "L5S_UNUSED";
						subsys-name = "Spare";
						phandle = <0xa2>;
					};

					LDO6S {
						regulator-name = "S2MPG11_LDO6";
						regulator-min-microvolt = <0x2625a0>;
						regulator-max-microvolt = <0x325aa0>;
						regulator-boot-on;
						regulator-initial-mode = <0x03>;
						channel-mux-selection = <0x26>;
						schematic-name = "L6S_PROX";
						subsys-name = "Sensors";
						phandle = <0x2c>;
					};

					LDO7S {
						regulator-name = "S2MPG11_LDO7";
						regulator-min-microvolt = <0x186a00>;
						regulator-max-microvolt = <0x1dc130>;
						regulator-boot-on;
						regulator-initial-mode = <0x03>;
						channel-mux-selection = <0x27>;
						schematic-name = "L7S_SENSORS";
						subsys-name = "Sensors";
						phandle = <0x2b>;
					};

					LDO8S {
						regulator-name = "S2MPG11_LDO8";
						regulator-min-microvolt = <0x113578>;
						regulator-max-microvolt = <0x138288>;
						regulator-always-on;
						regulator-initial-mode = <0x01>;
						channel-mux-selection = <0x28>;
						schematic-name = "L8S_UFS_VCCQ";
						subsys-name = "UFS";
						phandle = <0xa3>;
					};

					LDO9S {
						regulator-name = "S2MPG11_LDO9";
						regulator-min-microvolt = <0xb1008>;
						regulator-max-microvolt = <0x13d620>;
						regulator-always-on;
						regulator-initial-mode = <0x03>;
						channel-mux-selection = <0x29>;
						schematic-name = "L9S_GNSS_CORE";
						subsys-name = "GPS";
						phandle = <0xa4>;
					};

					LDO10S {
						regulator-name = "S2MPG11_LDO10";
						regulator-min-microvolt = <0x186a00>;
						regulator-max-microvolt = <0x1dc130>;
						regulator-always-on;
						regulator-initial-mode = <0x03>;
						channel-mux-selection = <0x2a>;
						schematic-name = "L10S_GNSS_RF";
						subsys-name = "GPS";
						phandle = <0xa5>;
					};

					LDO11S {
						regulator-name = "S2MPG11_LDO11";
						regulator-min-microvolt = <0x186a00>;
						regulator-max-microvolt = <0x1dc130>;
						regulator-always-on;
						regulator-initial-mode = <0x03>;
						channel-mux-selection = <0x2b>;
						schematic-name = "L11S_GNSS_AUX";
						subsys-name = "GPS";
						phandle = <0xa6>;
					};

					LDO12S {
						regulator-name = "S2MPG11_LDO12";
						regulator-min-microvolt = <0x186a00>;
						regulator-max-microvolt = <0x1dc130>;
						channel-mux-selection = <0x2c>;
						schematic-name = "L12S_UNUSED";
						subsys-name = "Spare";
						phandle = <0xa7>;
					};

					LDO13S {
						regulator-name = "S2MPG11_LDO13";
						regulator-min-microvolt = <0x1b7740>;
						regulator-max-microvolt = <0x331df0>;
						regulator-always-on;
						regulator-initial-mode = <0x01>;
						channel-mux-selection = <0x2d>;
						schematic-name = "L13S_DPAUX";
						subsys-name = "Display";
						phandle = <0xa8>;
					};

					LDO14S {
						regulator-name = "S2MPG11_LDO14";
						regulator-min-microvolt = <0x186a00>;
						regulator-max-microvolt = <0x1dc130>;
						regulator-initial-mode = <0x03>;
						channel-mux-selection = <0x2e>;
						schematic-name = "L14S_UWB";
						subsys-name = "UWB";
						phandle = <0xa9>;
					};

					LDO15S {
						regulator-name = "S2MPG11_LDO15";
						regulator-min-microvolt = <0x186a00>;
						regulator-max-microvolt = <0x1dc130>;
						channel-mux-selection = <0x2f>;
						schematic-name = "L15S_UNUSED";
						subsys-name = "Spare";
						phandle = <0xaa>;
					};
				};

				odpm {
					chip-name = "S2MPG11";
					sample-rate-uhz = <0x7735940>;
					sample-rate-external-uhz = <0x1d19574>;
					max-refresh-time-ms = <0xdbba0>;

					channels {

						channel@0 {
							rail-name = "VSEN_C6";
							channel_enabled;
							phandle = <0xab>;
						};

						channel@1 {
							rail-name = "LDO2S";
							channel_enabled;
							phandle = <0xac>;
						};

						channel@2 {
							rail-name = "BUCK9S";
							channel_enabled;
							phandle = <0xad>;
						};

						channel@3 {
							rail-name = "BUCK5S";
							channel_enabled;
							phandle = <0xae>;
						};

						channel@4 {
							rail-name = "BUCK10S";
							channel_enabled;
							phandle = <0xaf>;
						};

						channel@5 {
							rail-name = "BUCK4S";
							channel_enabled;
							phandle = <0xb0>;
						};

						channel@6 {
							rail-name = "BUCK2S";
							channel_enabled;
							phandle = <0xb1>;
						};

						channel@7 {
							rail-name = "VSEN_C4";
							channel_enabled;
							phandle = <0xb2>;
						};
					};

					rails {
						use-regulators-as-rails;

						VSEN_C4 {
							external_rail;
							channel-en-index = <0x01>;
							channel-mux-selection = <0x5c>;
							shunt-res-uohms = <0x2710>;
							schematic-name = "VSYS_PWR_DISPLAY";
							subsys-name = "Display";
							phandle = <0xb3>;
						};

						VSEN_C5 {
							external_rail;
							channel-en-index = <0x02>;
							channel-mux-selection = <0x5d>;
							shunt-res-uohms = <0x2710>;
							schematic-name = "VSEN_C5_NC";
							subsys-name = "Spare";
							phandle = <0xb4>;
						};

						VSEN_C6 {
							external_rail;
							channel-en-index = <0x04>;
							channel-mux-selection = <0x5e>;
							shunt-res-uohms = <0x2710>;
							schematic-name = "VSYS_PWR_MMWAVE";
							subsys-name = "Cellular";
							phandle = <0xb5>;
						};
					};
				};

				s2mpg11_gpio {
					gpio-controller;
					#gpio-cells = <0x02>;
					ngpios = <0x06>;
					gpio-ranges = <0x1b 0x00 0x00 0x06>;
					phandle = <0x2d>;
				};

				s2mpg11_pinctrl {
					phandle = <0x1b>;
				};
			};
		};
	};

	fragment@16 {
		target = <0xffffffff>;

		__overlay__ {
			main-pmic = <0x1c>;
			sub-pmic = <0x1d>;
			acpm-ipc-channel = <0x02>;
		};
	};

	fragment@17 {
		target = <0xffffffff>;

		__overlay__ {
			status = "okay";
		};
	};

	fragment@18 {
		target = <0xffffffff>;

		__overlay__ {

			key-voldown {
				samsung,pins = "gpa7-3";
				samsung,pin-function = <0x0f>;
				samsung,pin-pud = <0x00>;
				samsung,pin-drv = <0x00>;
				phandle = <0x1e>;
			};

			key-volup {
				samsung,pins = "gpa8-1";
				samsung,pin-function = <0x0f>;
				samsung,pin-pud = <0x00>;
				samsung,pin-drv = <0x00>;
				phandle = <0x1f>;
			};
		};
	};

	fragment@19 {
		target = <0xffffffff>;

		__overlay__ {

			key-power {
				samsung,pins = "gpa10-1";
				samsung,pin-function = <0x0f>;
				samsung,pin-pud = <0x00>;
				samsung,pin-drv = <0x00>;
				phandle = <0x20>;
			};
		};
	};

	fragment@20 {
		target = <0xffffffff>;

		__overlay__ {
			status = "okay";
			pinctrl-names = "default";
			pinctrl-0 = <0x1e 0x1f 0x20>;

			button@1 {
				label = "gpio-keys: KEY_VOLUMEDOWN";
				linux,code = <0x72>;
				gpios = <0xffffffff 0x03 0x0f>;
				wakeup-source;
			};

			button@2 {
				label = "gpio-keys: KEY_VOLUMEUP";
				linux,code = <0x73>;
				gpios = <0xffffffff 0x01 0x0f>;
				wakeup-source;
			};

			button@3 {
				label = "gpio-keys: KEY_POWER";
				linux,code = <0x74>;
				gpios = <0xffffffff 0x01 0x0f>;
				wakeup-source;
			};
		};
	};

	fragment@21 {
		target = <0xffffffff>;

		__overlay__ {
			usb3-lpm-capable;
			adj-sof-accuracy = <0x01>;
			samsung,no-extra-delay;
			usb_host_device_timeout = <0x7ff>;
			extcon = <0x13>;
			u1u2_exitfail_quirk;
			ux_exit_in_px_quirk;
			elastic_buf_mode_quirk;
			xhci_l2_support = <0x01>;

			dwc3 {
				dr_mode = "peripheral";
				maximum-speed = "super-speed-plus";
				usb3-lpm-capable;
				usb-psy-name = "usb";
				snps,quirk-frame-length-adjustment = <0x20>;
				snps,usb3_lpm_capable;
				snps,has-lpm-erratum;
				snps,lpm-nyet-threshold = <0x00>;
				snps,usb2-gadget-lpm-disable;
				snps,dis-u2-freeclk-exists-quirk;
				snps,dis-u1-entry-quirk;
				snps,dis-u2-entry-quirk;
				xhci_l2_support = <0x01>;
				phandle = <0xb6>;
			};
		};
	};

	fragment@22 {
		target = <0xffffffff>;

		__overlay__ {

			hs_tune {
				status = "disabled";
				hs_tune_cnt = <0x06>;
				phandle = <0x21>;

				hs_tune1 {
					tune_name = "tx_pre_emp";
					tune_value = <0x03 0x03>;
				};

				hs_tune2 {
					tune_name = "tx_vref";
					tune_value = <0x0f 0x0f>;
				};

				hs_tune3 {
					tune_name = "rx_sqrx";
					tune_value = <0x05 0x05>;
				};

				hs_tune4 {
					tune_name = "utmi_clk";
					tune_value = <0x01 0x01>;
				};

				hs_tune5 {
					tune_name = "compdis";
					tune_value = <0x07 0x07>;
				};

				hs_tune6 {
					tune_name = "tx_res";
					tune_value = <0x03 0x03>;
				};
			};

			ss_tune {
				status = "disabled";
				ss_tune_cnt = <0x24>;
				phandle = <0x22>;

				ss_tune1 {
					tune_name = "ssrx_sqhs_th_ss";
					tune_value = <0xffffffff 0xffffffff>;
				};

				ss_tune2 {
					tune_name = "ssrx_sqhs_th_ssp";
					tune_value = <0xffffffff 0xffffffff>;
				};

				ss_tune3 {
					tune_name = "ssrx_lfps_th";
					tune_value = <0xffffffff 0xffffffff>;
				};

				ss_tune4 {
					tune_name = "ssrx_adap_coef_sel";
					tune_value = <0xffffffff 0xffffffff>;
				};

				ss_tune5 {
					tune_name = "ssrx_mf_eq_psel_ctrl_ss";
					tune_value = <0xffffffff 0xffffffff>;
				};

				ss_tune6 {
					tune_name = "ssrx_mf_eq_psel_ctrl_ssp";
					tune_value = <0xffffffff 0xffffffff>;
				};

				ss_tune7 {
					tune_name = "ssrx_mf_eq_zsel_ctrl_ss";
					tune_value = <0xffffffff 0xffffffff>;
				};

				ss_tune8 {
					tune_name = "ssrx_mf_eq_zsel_ctrl_ssp";
					tune_value = <0xffffffff 0xffffffff>;
				};

				ss_tune9 {
					tune_name = "ssrx_hf_eq_rsel_ctrl_ss";
					tune_value = <0xffffffff 0xffffffff>;
				};

				ss_tune10 {
					tune_name = "ssrx_hf_eq_rsel_ctrl_ssp";
					tune_value = <0xffffffff 0xffffffff>;
				};

				ss_tune11 {
					tune_name = "ssrx_hf_eq_csel_ctrl_ss";
					tune_value = <0xffffffff 0xffffffff>;
				};

				ss_tune12 {
					tune_name = "ssrx_hf_eq_csel_ctrl_ssp";
					tune_value = <0xffffffff 0xffffffff>;
				};

				ss_tune13 {
					tune_name = "ssrx_dfe_1tap_ctrl_ss";
					tune_value = <0xffffffff 0xffffffff>;
				};

				ss_tune14 {
					tune_name = "ssrx_dfe_1tap_ctrl_ssp";
					tune_value = <0xffffffff 0xffffffff>;
				};

				ss_tune15 {
					tune_name = "ssrx_dfe_2tap_ctrl_ss";
					tune_value = <0xffffffff 0xffffffff>;
				};

				ss_tune16 {
					tune_name = "ssrx_dfe_2tap_ctrl_ssp";
					tune_value = <0xffffffff 0xffffffff>;
				};

				ss_tune17 {
					tune_name = "ssrx_dfe_3tap_ctrl_ss";
					tune_value = <0xffffffff 0xffffffff>;
				};

				ss_tune18 {
					tune_name = "ssrx_dfe_3tap_ctrl_ssp";
					tune_value = <0xffffffff 0xffffffff>;
				};

				ss_tune19 {
					tune_name = "ssrx_dfe_4tap_ctrl_ss";
					tune_value = <0xffffffff 0xffffffff>;
				};

				ss_tune20 {
					tune_name = "ssrx_dfe_4tap_ctrl_ssp";
					tune_value = <0xffffffff 0xffffffff>;
				};

				ss_tune21 {
					tune_name = "ssrx_dfe_5tap_ctrl_ss";
					tune_value = <0xffffffff 0xffffffff>;
				};

				ss_tune22 {
					tune_name = "ssrx_dfe_5tap_ctrl_ssp";
					tune_value = <0xffffffff 0xffffffff>;
				};

				ss_tune23 {
					tune_name = "ssrx_term_cal";
					tune_value = <0xffffffff 0xffffffff>;
				};

				ss_tune24 {
					tune_name = "sstx_amp_ss";
					tune_value = <0xffffffff 0xffffffff>;
				};

				ss_tune25 {
					tune_name = "sstx_deemp_ss";
					tune_value = <0xffffffff 0xffffffff>;
				};

				ss_tune26 {
					tune_name = "sstx_pre_shoot_ss";
					tune_value = <0xffffffff 0xffffffff>;
				};

				ss_tune27 {
					tune_name = "sstx_amp_ssp";
					tune_value = <0xffffffff 0xffffffff>;
				};

				ss_tune28 {
					tune_name = "sstx_deemp_ssp";
					tune_value = <0xffffffff 0xffffffff>;
				};

				ss_tune29 {
					tune_name = "sstx_pre_shoot_ssp";
					tune_value = <0xffffffff 0xffffffff>;
				};

				ss_tune30 {
					tune_name = "sstx_idrv_up";
					tune_value = <0xffffffff 0xffffffff>;
				};

				ss_tune31 {
					tune_name = "sstx_lfps_idrv_up";
					tune_value = <0xffffffff 0xffffffff>;
				};

				ss_tune32 {
					tune_name = "sstx_up_term";
					tune_value = <0xffffffff 0xffffffff>;
				};

				ss_tune33 {
					tune_name = "sstx_dn_term";
					tune_value = <0xffffffff 0xffffffff>;
				};

				ss_tune34 {
					tune_name = "rext_ovrd";
					tune_value = <0xffffffff 0xffffffff>;
				};

				ss_tune35 {
					tune_name = "ssrx_cdr_fbb_fine_ctrl_sp";
					tune_value = <0xffffffff 0xffffffff>;
				};

				ss_tune36 {
					tune_name = "ssrx_cdr_fbb_fine_ctrl_ssp";
					tune_value = <0xffffffff 0xffffffff>;
				};
			};
		};
	};

	fragment@23 {
		target = <0xffffffff>;

		__overlay__ {
			status = "okay";
			hs_tune_param = <0x21>;
			ss_tune_param = <0x22>;
			extcon = <0x13>;
		};
	};

	fragment@24 {
		target = <0xffffffff>;

		__overlay__ {
			vdd_hsi-supply = <0x23>;
			vdd085-supply = <0x24>;
			vdd18-supply = <0x25>;
			vdd30-supply = <0x26>;
		};
	};

	fragment@25 {
		target = <0xffffffff>;

		__overlay__ {
			status = "okay";
			use-cache-coherency = "true";
			use-msi = "true";
			use-sicd = "true";
			use-ia = "true";
			use-l1ss = "true";
			phy-power-off = "false";
			use-pcieon-sleep = "true";
			ep-device-type = <0x04>;
			vreg1-supply = <0x27>;
			vreg2-supply = <0x28>;
		};
	};

	fragment@26 {
		target = <0xffffffff>;

		__overlay__ {
			status = "okay";
			num-lanes = <0x01>;
			use-sicd = "true";
			use-ia = "true";
			use-l1ss = "true";
			use-phy-isol-en = "true";
			max-link-speed = <0x02>;
			ep-device-type = <0x01>;
			pcie,wlan-gpio = <0xffffffff 0x02 0x01>;
			vreg1-supply = <0x29>;
			vreg2-supply = <0x2a>;
		};
	};

	fragment@27 {
		target = <0xffffffff>;

		__overlay__ {
			sensor_1v8-supply = <0x2b>;
			sensor_3v3-supply = <0x2c>;
			sensor_power_list = "sensor_1v8\0sensor_3v3";
		};
	};

	fragment@28 {
		target = <0xffffffff>;

		__overlay__ {
			sensor_1v8-supply = <0x2b>;
			sensor_3v3-supply = <0x2c>;
			sensor_power_list = "sensor_1v8\0sensor_3v3";
		};
	};

	fragment@29 {
		target = <0xffffffff>;

		__overlay__ {
			status = "ok";
			#address-cells = <0x01>;
			#size-cells = <0x00>;

			slg51000@75 {
				compatible = "dlg,slg51000";
				reg = <0x75>;
				status = "ok";
				dlg,cs-gpios = <0x2d 0x00 0x00>;
				phandle = <0xb7>;

				regulators {

					ldo1 {
						regulator-name = "ldo1";
						regulator-min-microvolt = <0x225510>;
						regulator-max-microvolt = <0x325aa0>;
						phandle = <0x34>;
					};

					ldo2 {
						regulator-name = "ldo2";
						regulator-min-microvolt = <0x225510>;
						regulator-max-microvolt = <0x325aa0>;
						phandle = <0x39>;
					};

					ldo3 {
						regulator-name = "ldo3";
						regulator-min-microvolt = <0x124f80>;
						regulator-max-microvolt = <0x393870>;
						phandle = <0x35>;
					};

					ldo4 {
						regulator-name = "ldo4";
						regulator-min-microvolt = <0x124f80>;
						regulator-max-microvolt = <0x393870>;
						phandle = <0x36>;
					};

					ldo5 {
						regulator-name = "ldo5";
						regulator-min-microvolt = <0x7a120>;
						regulator-max-microvolt = <0x124f80>;
						phandle = <0x3a>;
					};

					ldo6 {
						regulator-name = "ldo6";
						regulator-min-microvolt = <0x7a120>;
						regulator-max-microvolt = <0x124f80>;
						phandle = <0x37>;
					};

					ldo7 {
						regulator-name = "ldo7";
						regulator-min-microvolt = <0x124f80>;
						regulator-max-microvolt = <0x393870>;
						phandle = <0x38>;
					};
				};
			};
		};
	};

	fragment@30 {
		target = <0xffffffff>;

		__overlay__ {

			hsi2c2-bus {
				samsung,pin-pud = <0x03>;
				phandle = <0x2f>;
			};

			hsi2c2-bus-in {
				samsung,pins = "gpp4-0\0gpp4-1";
				samsung,pin-function = <0x00>;
				samsung,pin-pud = <0x00>;
				samsung,pin-drv = <0x00>;
				phandle = <0x2e>;
			};

			hsi2c3-bus {
				samsung,pin-pud = <0x03>;
				phandle = <0x31>;
			};

			hsi2c3-bus-in {
				samsung,pins = "gpp6-0\0gpp6-1";
				samsung,pin-function = <0x00>;
				samsung,pin-pud = <0x00>;
				samsung,pin-drv = <0x00>;
				phandle = <0x30>;
			};

			hsi2c4-bus {
				samsung,pin-pud = <0x03>;
				phandle = <0x33>;
			};

			hsi2c4-bus-in {
				samsung,pins = "gpp8-0\0gpp8-1";
				samsung,pin-function = <0x00>;
				samsung,pin-pud = <0x00>;
				samsung,pin-drv = <0x00>;
				phandle = <0x32>;
			};
		};
	};

	fragment@31 {
		target = <0xffffffff>;

		__overlay__ {

			flash_active {
				samsung,pins = "gpp27-1";
				samsung,pin-function = <0x01>;
				samsung,pin-pud = <0x00>;
				phandle = <0x3b>;
			};

			flash_suspend {
				samsung,pins = "gpp27-1";
				samsung,pin-function = <0x00>;
				samsung,pin-pud = <0x01>;
				phandle = <0x3c>;
			};
		};
	};

	fragment@32 {
		target = <0xffffffff>;

		__overlay__ {
			#address-cells = <0x01>;
			#size-cells = <0x00>;
			gpios = <0xffffffff 0x00 0x00 0xffffffff 0x01 0x00>;
			status = "okay";
			clock-frequency = <0xf4240>;
			samsung,reset-before-trans;
			pinctrl-names = "default\0on_i2c\0off_i2c";
			pinctrl-0 = <0x2e>;
			pinctrl-1 = <0x2f>;
			pinctrl-2 = <0x2e>;
		};
	};

	fragment@33 {
		target = <0xffffffff>;

		__overlay__ {
			#address-cells = <0x01>;
			#size-cells = <0x00>;
			gpios = <0xffffffff 0x00 0x00 0xffffffff 0x01 0x00>;
			status = "okay";
			clock-frequency = <0xf4240>;
			samsung,reset-before-trans;
			pinctrl-names = "default\0on_i2c\0off_i2c";
			pinctrl-0 = <0x30>;
			pinctrl-1 = <0x31>;
			pinctrl-2 = <0x30>;
		};
	};

	fragment@34 {
		target = <0xffffffff>;

		__overlay__ {
			#address-cells = <0x01>;
			#size-cells = <0x00>;
			gpios = <0xffffffff 0x00 0x00 0xffffffff 0x01 0x00>;
			status = "okay";
			clock-frequency = <0xf4240>;
			samsung,reset-before-trans;
			pinctrl-names = "default\0on_i2c\0off_i2c";
			pinctrl-0 = <0x32>;
			pinctrl-1 = <0x33>;
			pinctrl-2 = <0x32>;
		};
	};

	fragment@35 {
		target = <0xffffffff>;

		__overlay__ {
			#address-cells = <0x01>;
			#size-cells = <0x00>;
			gpios = <0xffffffff 0x00 0x00 0xffffffff 0x01 0x00>;
			status = "okay";
			clock-frequency = <0x61a80>;
			pinctrl-names = "default\0on_i2c\0off_i2c";
			pinctrl-0 = <0xffffffff>;
			pinctrl-1 = <0xffffffff>;
			pinctrl-2 = <0xffffffff>;
		};
	};

	fragment@lwiscamera {
		target-path = "/";

		__overlay__ {

			sensor@0 {
				compatible = "google,lwis-i2c-device";
				node-name = "sensor0";
				i2c-bus = <0xffffffff>;
				i2c-addr = <0x10>;
				reg-addr-bitwidth = <0x10>;
				reg-value-bitwidth = <0x08>;
				enable-gpios = <0x2d 0x03 0x00>;
				reset-gpios = <0xffffffff 0x03 0x00>;
				regulators = <0x34 0x35 0x36 0x37 0x38>;
				regulator-voltages = <0x2b7cd0 0x2b7cd0 0x1b7740 0x10c8e0 0x1b7740>;
				clocks = <0xffffffff 0x3b 0xffffffff 0x32>;
				clock-names = "CIS_CLK0\0GATE_DFTMUX_CMU_CIS_CLK0";
				clock-rates = <0x16e3600 0x00>;
				pinctrl-names = "mclk_on\0mclk_off";
				pinctrl-0 = <0xffffffff>;
				pinctrl-1 = <0xffffffff>;
				phandle = <0xb8>;
			};

			sensor@2 {
				compatible = "google,lwis-i2c-device";
				node-name = "sensor2";
				i2c-bus = <0xffffffff>;
				i2c-addr = <0x1a>;
				reg-addr-bitwidth = <0x10>;
				reg-value-bitwidth = <0x08>;
				enable-gpios = <0x2d 0x01 0x00>;
				reset-gpios = <0xffffffff 0x02 0x00>;
				regulators = <0x38>;
				regulator-voltages = <0x1b7740>;
				clocks = <0xffffffff 0x3c 0xffffffff 0x33>;
				clock-names = "CIS_CLK1\0GATE_DFTMUX_CMU_CIS_CLK1";
				clock-rates = <0x16e3600 0x00>;
				pinctrl-names = "mclk_on\0mclk_off";
				pinctrl-0 = <0xffffffff>;
				pinctrl-1 = <0xffffffff>;
				phandle = <0xb9>;
			};

			sensor@1 {
				compatible = "google,lwis-i2c-device";
				node-name = "sensor1";
				i2c-bus = <0xffffffff>;
				i2c-addr = <0x1a>;
				reg-addr-bitwidth = <0x10>;
				reg-value-bitwidth = <0x08>;
				enable-gpios = <0x2d 0x02 0x00>;
				reset-gpios = <0xffffffff 0x02 0x00>;
				regulators = <0x39 0x35 0x3a 0x38>;
				regulator-voltages = <0x2b7cd0 0x2b7cd0 0x10c8e0 0x1b7740>;
				clocks = <0xffffffff 0x3d 0xffffffff 0x34>;
				clock-names = "CIS_CLK2\0GATE_DFTMUX_CMU_CIS_CLK2";
				clock-rates = <0x16e3600 0x00>;
				pinctrl-names = "mclk_on\0mclk_off";
				pinctrl-0 = <0xffffffff>;
				pinctrl-1 = <0xffffffff>;
				phandle = <0xba>;
			};

			actuator@0 {
				compatible = "google,lwis-i2c-device";
				node-name = "act0";
				i2c-bus = <0xffffffff>;
				i2c-addr = <0x3b>;
				reg-addr-bitwidth = <0x10>;
				reg-value-bitwidth = <0x20>;
				enable-gpios = <0x2d 0x04 0x00>;
				regulators = <0x35 0x38>;
				regulator-voltages = <0x2b7cd0 0x1b7740>;
				clocks = <0xffffffff 0x3b 0xffffffff 0x32>;
				clock-names = "CIS_CLK0\0GATE_DFTMUX_CMU_CIS_CLK0";
				clock-rates = <0x16e3600 0x00>;
				phandle = <0xbb>;
			};

			eeprom@0 {
				compatible = "google,lwis-i2c-device";
				node-name = "eeprom0";
				i2c-bus = <0xffffffff>;
				i2c-addr = <0x3b>;
				reg-addr-bitwidth = <0x10>;
				reg-value-bitwidth = <0x20>;
				enable-gpios = <0x2d 0x03 0x00 0x2d 0x04 0x00>;
				reset-gpios = <0xffffffff 0x03 0x00>;
				regulators = <0x38>;
				regulator-voltages = <0x1b7740>;
				clocks = <0xffffffff 0x3b 0xffffffff 0x32>;
				clock-names = "CIS_CLK0\0GATE_DFTMUX_CMU_CIS_CLK0";
				clock-rates = <0x16e3600 0x00>;
				phandle = <0xbc>;
			};

			eeprom@1 {
				compatible = "google,lwis-i2c-device";
				node-name = "eeprom1";
				i2c-bus = <0xffffffff>;
				i2c-addr = <0x50>;
				reg-addr-bitwidth = <0x10>;
				reg-value-bitwidth = <0x08>;
				enable-gpios = <0x2d 0x02 0x00>;
				reset-gpios = <0xffffffff 0x02 0x00>;
				regulators = <0x39 0x35 0x3a 0x38>;
				regulator-voltages = <0x2b7cd0 0x2b7cd0 0x10c8e0 0x1b7740>;
				clocks = <0xffffffff 0x3d 0xffffffff 0x34>;
				clock-names = "CIS_CLK2\0GATE_DFTMUX_CMU_CIS_CLK2";
				clock-rates = <0x16e3600 0x00>;
				phandle = <0xbd>;
			};

			eeprom@2 {
				compatible = "google,lwis-i2c-device";
				node-name = "eeprom2";
				i2c-bus = <0xffffffff>;
				i2c-addr = <0x51>;
				reg-addr-bitwidth = <0x10>;
				reg-value-bitwidth = <0x08>;
				enable-gpios = <0x2d 0x01 0x00>;
				reset-gpios = <0xffffffff 0x02 0x00>;
				regulators = <0x38>;
				regulator-voltages = <0x1b7740>;
				clocks = <0xffffffff 0x3c 0xffffffff 0x33>;
				clock-names = "CIS_CLK1\0GATE_DFTMUX_CMU_CIS_CLK1";
				clock-rates = <0x16e3600 0x00>;
				phandle = <0xbe>;
			};

			flash@0 {
				compatible = "google,lwis-i2c-device";
				node-name = "flash0";
				i2c-bus = <0xffffffff>;
				i2c-addr = <0x63>;
				reg-addr-bitwidth = <0x08>;
				reg-value-bitwidth = <0x08>;
				pinctrl-names = "mclk_on\0mclk_off";
				pinctrl-0 = <0x3b>;
				pinctrl-1 = <0x3c>;
				enable-gpios = <0xffffffff 0x01 0x00 0xffffffff 0x00 0x01 0xffffffff 0x02 0x01>;
				phandle = <0xbf>;
			};
		};
	};

	fragment@36 {
		target = <0xffffffff>;

		__overlay__ {

			goodixfp {
				status = "okay";
				compatible = "goodix,fingerprint";
				interrupt-parent = <0xffffffff>;
				interrupts = <0x07 0x00>;
				spi-max-frequency = <0xf4240>;
				pinctrl-names = "default";
				fp-gpio-irq = <0xffffffff 0x07 0x00>;
				fp-gpio-reset = <0xffffffff 0x03 0x01>;
			};
		};
	};

	fragment@battery {
		target-path = "/";

		__overlay__ {

			google,battery {
				status = "okay";
				compatible = "google,battery";
				#cooling-cells = <0x02>;
				google,fg-psy-name = "maxfg";
				google,chg-battery-capacity = <0xfa0>;
				google,chg-temp-limits = <0x00 0x64 0xc8 0x1a4 0x1cc 0x1e0 0x226>;
				google,chg-cv-limits = <0x401640 0x419ce0 0x432380>;
				google,chg-cc-limits = <0x1e 0x0a 0x00 0x32 0x1e 0x1e 0x64 0x46 0x32 0x50 0x32 0x32 0x32 0x32 0x00 0x1e 0x00 0x00>;
				#thermal-sensor-cells = <0x00>;
				phandle = <0x5b>;
			};

			google,cpm {
				status = "okay";
				compatible = "google,cpm";
				google,chg-power-supplies = "main-charger";
				phandle = <0xc0>;
			};

			google,charger {
				status = "okay";
				compatible = "google,charger";
				#cooling-cells = <0x02>;
				google,chg-power-supply = "gcpm";
				google,bat-power-supply = "battery";
				google,usb-power-supply = "usb";
				google,fv-max-uv = <0x432380>;
				google,thermal-mitigation = <0x3d0900 0x2dc6c0 0x1e8480 0xf4240 0x7a120>;
				google,wlc-thermal-mitigation = <0x10c8e0 0x7a120 0x3d090 0x1adb0>;
				google,therm-wlc-overrides-fcc;
				phandle = <0xc1>;
			};

			google_bms {
				nvmem = <0x3d>;
				nvmem-names = "5-00500";
				google,bee-name = "5-00500";
			};

			google,mitigation {
				compatible = "google,google-bcl";
				#thermal-sensor-cells = <0x01>;
				google,charger = <0x3e>;
				google,power-supply = <0x3f>;
				google,main-power = <0x1c>;
				google,sub-power = <0x1d>;
				ppm_settings = <0x00>;
				mpmm_settings = <0x1a>;
				tpu_con_heavy = <0xf041c3>;
				tpu_con_light = <0xf041c5>;
				tpu_clkdivstep = <0x201>;
				gpu_con_heavy = <0xf04385>;
				gpu_con_light = <0x00>;
				gpu_clkdivstep = <0x801>;
				cpu2_clkdivstep = <0x801>;
				cpu1_clkdivstep = <0x00>;
				cpu0_clkdivstep = <0x01>;
				gpios = <0xffffffff 0x05 0x00 0xffffffff 0x06 0x00>;
				phandle = <0x5a>;
			};
		};
	};

	fragment@37 {
		target = <0xffffffff>;

		__overlay__ {
			#address-cells = <0x01>;
			#size-cells = <0x00>;
			status = "okay";
			pinctrl-names = "default";
			pinctrl-0 = <0xffffffff>;

			m24c08@50 {
				status = "okay";
				compatible = "at,24c08";
				reg = <0x50>;
				phandle = <0x3d>;
			};
		};
	};

	fragment@38 {
		target = <0xffffffff>;

		__overlay__ {
			samsung,pins = "gpp23-4\0gpp23-5";
			samsung,pin-pud = <0x03>;
		};
	};

	fragment@modemif {
		target-path = "/";

		__overlay__ {
			#address-cells = <0x02>;
			#size-cells = <0x01>;

			cpif {
				compatible = "samsung,exynos-cp";
				status = "okay";
				pci_ch_num = <0x00>;
				pci_db_addr = <0x40060000>;
				cpboot_spi_bus_num = <0x09>;
				s2mpu = <0xffffffff>;
				mif,name = "s5123";
				mif,cp_num = <0x00>;
				mif,modem_type = <0x01>;
				mif,protocol = <0x01>;
				mif,ipc_version = <0x32>;
				mif,link_type = <0x01>;
				mif,link_name = "PCIE";
				mif,link_attrs = <0xfc8>;
				mif,interrupt_types = <0x01>;
				mif,capability_check = <0x01>;
				mif,int_ap2cp_msg = <0x00>;
				mif,int_ap2cp_wakeup = <0x01>;
				mif,int_ap2cp_status = <0x02>;
				mif,int_ap2cp_active = <0x03>;
				mif,int_ap2cp_lcd_status = <0x04>;
				mif,int_ap2cp_pcie_link_ack = <0x0e>;
				mif,int_ap2cp_uart_noti = <0x0f>;
				mif,irq_cp2ap_msg = <0x00>;
				mif,irq_cp2ap_status = <0x02>;
				mif,irq_cp2ap_active = <0x03>;
				mif,irq_cp2ap_wakelock = <0x08>;
				mif,irq_cp2ap_ratmode = <0x09>;
				legacy_fmt_head_tail_offset = <0x08>;
				legacy_fmt_buffer_offset = <0x1000>;
				legacy_fmt_txq_size = <0x1000>;
				legacy_fmt_rxq_size = <0x1000>;
				legacy_raw_head_tail_offset = <0x18>;
				legacy_raw_buffer_offset = <0x3000>;
				legacy_raw_txq_size = <0x1fd000>;
				legacy_raw_rxq_size = <0x200000>;
				legacy_raw_rx_buffer_cached = <0x00>;
				offset_srinfo_offset = <0x64>;
				offset_capability_offset = <0x70>;
				srinfo_offset = <0x300>;
				srinfo_size = <0x400>;
				capability_offset = <0xa0>;
				ap_capability_0 = <0x00>;
				ap_capability_1 = <0x00>;
				ap2cp_msg = <0x02 0x800>;
				cp2ap_msg = <0x02 0x804>;
				ap2cp_united_status = <0x02 0x808>;
				cp2ap_united_status = <0x02 0x80c>;
				ap2cp_kerneltime = <0x02 0x824>;
				ap2cp_handover_block_info = <0x02 0x82c>;
				sbi_lcd_status_mask = <0x01>;
				sbi_lcd_status_pos = <0x1b>;
				sbi_crash_type_mask = <0x0f>;
				sbi_crash_type_pos = <0x17>;
				sbi_uart_noti_mask = <0x01>;
				sbi_uart_noti_pos = <0x10>;
				sbi_ds_det_mask = <0x03>;
				sbi_ds_det_pos = <0x0e>;
				sbi_pda_active_mask = <0x01>;
				sbi_pda_active_pos = <0x05>;
				sbi_ap_status_mask = <0x0f>;
				sbi_ap_status_pos = <0x01>;
				sbi_cp_rat_mode_mask = <0x3f>;
				sbi_cp_rat_mode_pos = <0x1a>;
				sbi_cp2ap_wakelock_mask = <0x01>;
				sbi_cp2ap_wakelock_pos = <0x06>;
				sbi_lte_active_mask = <0x01>;
				sbi_lte_active_pos = <0x05>;
				sbi_cp_status_mask = <0x0f>;
				sbi_cp_status_pos = <0x01>;
				sbi_ap2cp_kerneltime_sec_mask = <0xfff>;
				sbi_ap2cp_kerneltime_sec_pos = <0x14>;
				sbi_ap2cp_kerneltime_usec_mask = <0xfffff>;
				sbi_ap2cp_kerneltime_usec_pos = <0x00>;
				pktproc_use_36bit_addr = <0x00>;
				pktproc_cp_base = <0x00 0x20000000>;
				pktproc_dl_support = <0x01>;
				pktproc_dl_version = <0x02>;
				pktproc_dl_info_rgn_offset = <0x00>;
				pktproc_dl_info_rgn_size = <0x1000>;
				pktproc_dl_desc_rgn_offset = <0x1000>;
				pktproc_dl_desc_rgn_size = <0xff000>;
				pktproc_dl_buff_rgn_offset = <0x100000>;
				pktproc_dl_buff_rgn_size = <0x1b00000>;
				pktproc_dl_info_rgn_cached = <0x01>;
				pktproc_dl_desc_rgn_cached = <0x01>;
				pktproc_dl_buff_rgn_cached = <0x01>;
				pktproc_dl_desc_mode = <0x01>;
				pktproc_dl_num_queue = <0x01>;
				pktproc_dl_use_exclusive_irq = <0x00>;
				pktproc_dl_use_hw_iocc = <0x01>;
				pktproc_dl_max_packet_size = <0x800>;
				pktproc_dl_use_dedicated_baaw = <0x00>;
				pktproc_ul_support = <0x01>;
				pktproc_ul_info_rgn_offset = <0x6000000>;
				pktproc_ul_info_rgn_size = <0x1000>;
				pktproc_ul_desc_rgn_offset = <0x6001000>;
				pktproc_ul_desc_rgn_size = <0x20000>;
				pktproc_ul_buff_rgn_offset = <0x6021000>;
				pktproc_ul_buff_rgn_size = <0x3df000>;
				pktproc_ul_padding_required = <0x01>;
				pktproc_ul_num_queue = <0x02>;
				pktproc_ul_max_packet_size = <0x800>;
				pktproc_ul_info_rgn_cached = <0x01>;
				pktproc_ul_desc_rgn_cached = <0x01>;
				pktproc_ul_buff_rgn_cached = <0x01>;
				pktproc_ul_use_hw_iocc = <0x01>;
				pinctrl-names = "default";
				pinctrl-0 = <0x40 0x41 0x42 0x43 0x44 0x45 0x46 0x47>;
				gpio_ap2cp_wake_up = <0xffffffff 0x02 0x01>;
				gpio_ap2cp_dump_noti = <0xffffffff 0x03 0x01>;
				gpio_ap2cp_cp_pwr_on = <0xffffffff 0x00 0x01>;
				gpio_ap2cp_pda_active = <0xffffffff 0x01 0x01>;
				gpio_ap2cp_nreset_n = <0xffffffff 0x03 0x01>;
				gpio_cp2ap_wake_up = <0xffffffff 0x04 0x01>;
				gpio_cp2ap_cp_ps_hold = <0xffffffff 0x05 0x01>;
				gpio_cp2ap_phone_active = <0xffffffff 0x05 0x01>;

				cpif_tpmon {
					trigger_msec_min = <0x1f4>;
					trigger_msec_max = <0x5dc>;
					monitor_interval_msec = <0x3e8>;
					monitor_hold_msec = <0xbb8>;
					monitor_stop_mbps = <0x0f>;
					boost_hold_msec = <0x1770>;

					tpmon_rps {
						boost_name = "RPS";
						target = <0x00>;
						extra_idx = <0x00>;
						level = <0x03 0x30 0xc0>;

						boost0 {
							enable = <0x01>;
							measure = <0x00>;
							proto = <0x00>;
							boost_threshold = <0xfa 0x640>;
							unboost_threshold_mbps = <0x64 0x258>;
						};
					};

					tpmon_gro_flush_time {
						boost_name = "GRO";
						target = <0x01>;
						extra_idx = <0x00>;
						level = <0x3d090 0x1e8480>;

						boost0 {
							enable = <0x01>;
							measure = <0x00>;
							proto = <0x00>;
							boost_threshold = <0x64>;
							unboost_threshold_mbps = <0x32>;
						};
					};

					tpmon_mif {
						boost_name = "MIF";
						target = <0x02>;
						extra_idx = <0x00>;
						level = <0x00 0xf78f0>;

						boost0 {
							enable = <0x01>;
							measure = <0x00>;
							proto = <0x01>;
							boost_threshold = <0x44c>;
							unboost_threshold_mbps = <0x190>;
						};
					};

					tpmon_cpu_cl0 {
						boost_name = "CL0";
						target = <0x09>;
						extra_idx = <0x00>;
						level = <0x00 0x104410 0x137090>;

						boost0 {
							enable = <0x00>;
							measure = <0x00>;
							proto = <0x01>;
							boost_threshold = <0x64 0x12c>;
							unboost_threshold_mbps = <0x28 0x78>;
						};
					};

					tpmon_cpu_cl1 {
						boost_name = "CL1";
						target = <0x0a>;
						extra_idx = <0x04>;
						level = <0x00 0x196018>;

						boost0 {
							enable = <0x01>;
							measure = <0x00>;
							proto = <0x00>;
							boost_threshold = <0x7d0>;
							unboost_threshold_mbps = <0x320>;
						};
					};

					tpmon_pcie_low_power {
						boost_name = "PCIE_LP";
						target = <0x03>;
						extra_idx = <0x00>;
						level = <0x01 0x00>;

						boost0 {
							enable = <0x01>;
							measure = <0x00>;
							proto = <0x00>;
							boost_threshold = <0xbb8>;
							unboost_threshold_mbps = <0x4b0>;
						};
					};

					tpmon_irq_affinity_0 {
						boost_name = "IRQ_0";
						target = <0x05>;
						extra_idx = <0x03>;
						level = <0x04 0x20>;

						boost0 {
							enable = <0x00>;
							measure = <0x00>;
							proto = <0x00>;
							boost_threshold = <0x1f4>;
							unboost_threshold_mbps = <0xc8>;
						};
					};

					tpmon_irq_dit {
						boost_name = "IRQ_DIT";
						target = <0x06>;
						extra_idx = <0x00>;
						level = <0x04 0x20>;

						boost0 {
							enable = <0x01>;
							measure = <0x00>;
							proto = <0x00>;
							boost_threshold = <0xfa>;
							unboost_threshold_mbps = <0x64>;
						};

						boost1 {
							enable = <0x01>;
							measure = <0x02>;
							proto = <0x00>;
							boost_threshold = <0x1770>;
							unboost_threshold_mbps = <0x7d0>;
						};

						boost2 {
							enable = <0x01>;
							measure = <0x03>;
							proto = <0x00>;
							boost_threshold = <0x1b58>;
							unboost_threshold_mbps = <0x7d0>;
						};
					};
				};

				iodevs {

					io_device_0 {
						iod,name = "umts_ipc";
						iod,ch = <0xf5>;
						iod,format = <0x00>;
						iod,io_type = <0x01>;
						iod,link_type = <0x01>;
						iod,attrs = <0x2000>;
						iod,ch_count = <0x02>;
					};

					io_device_1 {
						iod,name = "umts_rfs0";
						iod,ch = <0x29>;
						iod,format = <0x01>;
						iod,io_type = <0x01>;
						iod,link_type = <0x01>;
						iod,attrs = <0x00>;
					};

					io_device_2 {
						iod,name = "umts_router";
						iod,ch = <0x15>;
						iod,format = <0x01>;
						iod,io_type = <0x01>;
						iod,link_type = <0x01>;
						iod,attrs = <0x00>;
					};

					io_device_3 {
						iod,name = "umts_dm0";
						iod,ch = <0x51>;
						iod,format = <0x01>;
						iod,io_type = <0x01>;
						iod,link_type = <0x01>;
						iod,attrs = <0x4000>;
					};

					io_device_4 {
						iod,name = "umts_loopback";
						iod,ch = <0x52>;
						iod,format = <0x01>;
						iod,io_type = <0x01>;
						iod,link_type = <0x01>;
						iod,attrs = <0x00>;
					};

					io_device_5 {
						iod,name = "rmnet";
						iod,ch = <0xb5>;
						iod,format = <0x01>;
						iod,io_type = <0x02>;
						iod,link_type = <0x01>;
						iod,attrs = <0x2000>;
						iod,ch_count = <0x1e>;
					};

					io_device_6 {
						iod,name = "dummy";
						iod,ch = <0xd3>;
						iod,format = <0x01>;
						iod,io_type = <0x02>;
						iod,link_type = <0x01>;
						iod,attrs = <0x00>;
					};

					io_device_7 {
						iod,name = "multipdp";
						iod,ch = <0x00>;
						iod,format = <0x03>;
						iod,io_type = <0x03>;
						iod,link_type = <0x01>;
						iod,attrs = <0x00>;
					};

					io_device_8 {
						iod,name = "umts_boot0";
						iod,ch = <0xf1>;
						iod,format = <0x04>;
						iod,io_type = <0x00>;
						iod,link_type = <0x01>;
						iod,attrs = <0x200>;
					};

					io_device_9 {
						iod,name = "umts_rcs0";
						iod,ch = <0x5b>;
						iod,format = <0x00>;
						iod,io_type = <0x01>;
						iod,link_type = <0x01>;
						iod,attrs = <0x00>;
					};

					io_device_10 {
						iod,name = "umts_rcs1";
						iod,ch = <0x5c>;
						iod,format = <0x01>;
						iod,io_type = <0x01>;
						iod,link_type = <0x01>;
						iod,attrs = <0x00>;
					};

					io_device_11 {
						iod,name = "umts_wfc0";
						iod,ch = <0x5d>;
						iod,format = <0x00>;
						iod,io_type = <0x01>;
						iod,link_type = <0x01>;
						iod,attrs = <0x00>;
					};

					io_device_12 {
						iod,name = "umts_wfc1";
						iod,ch = <0x5e>;
						iod,format = <0x01>;
						iod,io_type = <0x01>;
						iod,link_type = <0x01>;
						iod,attrs = <0x00>;
					};

					io_device_13 {
						iod,name = "oem_ipc0";
						iod,ch = <0x81>;
						iod,format = <0x00>;
						iod,io_type = <0x01>;
						iod,link_type = <0x01>;
						iod,attrs = <0x00>;
					};

					io_device_14 {
						iod,name = "oem_ipc1";
						iod,ch = <0x82>;
						iod,format = <0x00>;
						iod,io_type = <0x01>;
						iod,link_type = <0x01>;
						iod,attrs = <0x00>;
					};

					io_device_15 {
						iod,name = "oem_ipc2";
						iod,ch = <0x83>;
						iod,format = <0x00>;
						iod,io_type = <0x01>;
						iod,link_type = <0x01>;
						iod,attrs = <0x00>;
					};

					io_device_16 {
						iod,name = "oem_ipc3";
						iod,ch = <0x84>;
						iod,format = <0x00>;
						iod,io_type = <0x01>;
						iod,link_type = <0x01>;
						iod,attrs = <0x00>;
					};

					io_device_17 {
						iod,name = "oem_ipc4";
						iod,ch = <0x85>;
						iod,format = <0x00>;
						iod,io_type = <0x01>;
						iod,link_type = <0x01>;
						iod,attrs = <0x00>;
					};

					io_device_18 {
						iod,name = "oem_ipc5";
						iod,ch = <0x86>;
						iod,format = <0x00>;
						iod,io_type = <0x01>;
						iod,link_type = <0x01>;
						iod,attrs = <0x00>;
					};

					io_device_19 {
						iod,name = "oem_ipc6";
						iod,ch = <0x87>;
						iod,format = <0x00>;
						iod,io_type = <0x01>;
						iod,link_type = <0x01>;
						iod,attrs = <0x00>;
					};

					io_device_20 {
						iod,name = "oem_ipc7";
						iod,ch = <0x88>;
						iod,format = <0x00>;
						iod,io_type = <0x01>;
						iod,link_type = <0x01>;
						iod,attrs = <0x00>;
					};
				};
			};

			cp_shmem {
				compatible = "samsung,exynos-cp-shmem";
				memory-region = <0xffffffff 0xffffffff 0xffffffff 0xffffffff>;
				cp_num = <0x00>;
				use_mem_map_on_cp = <0x00>;

				regions {

					ipc {
						region,name = "IPC";
						region,index = <0x03>;
						region,rmem = <0x00>;
						region,offset = <0x00>;
						region,size = <0x400000>;
						region,cached = <0x01>;
					};

					msi {
						region,name = "MSI";
						region,index = <0x0b>;
						region,rmem = <0x01>;
						region,offset = <0x00>;
						region,size = <0x1000>;
						region,cached = <0x00>;
					};

					pktproc {
						region,name = "PKTPROC";
						region,index = <0x07>;
						region,rmem = <0x02>;
						region,offset = <0x00>;
						region,size = <0x1c00000>;
					};

					pktproc_ul {
						region,name = "PKTPROC_UL";
						region,index = <0x08>;
						region,rmem = <0x03>;
						region,offset = <0x00>;
						region,size = <0x400000>;
					};
				};
			};
		};
	};

	fragment@39 {
		target = <0xffffffff>;

		__overlay__ {
			samsung,pin-con-pdn = <0x03>;
			samsung,pin-pud-pdn = <0x00>;
		};
	};

	fragment@40 {
		target = <0xffffffff>;

		__overlay__ {
			#address-cells = <0x01>;
			#size-cells = <0x00>;
			status = "okay";
			pinctrl-names = "default";
			pinctrl-0 = <0xffffffff 0xffffffff>;

			cpboot_spi@0 {
				compatible = "samsung,exynos-cp-spi";
				reg = <0x00>;
				spi-max-frequency = <0x20ce70>;

				controller-data {
					samsung,spi-feedback-delay = <0x00>;
					samsung,spi-chip-select-mode = <0x01>;
				};
			};
		};
	};

	fragment@41 {
		target = <0xffffffff>;

		__overlay__ {
			num_sensors = <0x09>;
		};
	};

	fragment@42 {
		target = <0xffffffff>;

		__overlay__ {

			cp_on_chip_0 {
				polling-delay-passive = <0x00>;
				polling-delay = <0x00>;
				thermal-governor = "user_space";
				thermal-sensors = <0xffffffff 0x00>;

				trips {

					trip_config {
						temperature = <0x1e848>;
						hysteresis = <0x3e8>;
						type = "passive";
					};
				};
			};

			cp_on_chip_1 {
				polling-delay-passive = <0x00>;
				polling-delay = <0x00>;
				thermal-governor = "user_space";
				thermal-sensors = <0xffffffff 0x01>;

				trips {

					trip_config {
						temperature = <0x1e848>;
						hysteresis = <0x3e8>;
						type = "passive";
					};
				};
			};

			cp_on_chip_2 {
				polling-delay-passive = <0x00>;
				polling-delay = <0x00>;
				thermal-governor = "user_space";
				thermal-sensors = <0xffffffff 0x02>;

				trips {

					trip_config {
						temperature = <0x1e848>;
						hysteresis = <0x3e8>;
						type = "passive";
					};
				};
			};

			cp_on_chip_3 {
				polling-delay-passive = <0x00>;
				polling-delay = <0x00>;
				thermal-governor = "user_space";
				thermal-sensors = <0xffffffff 0x03>;

				trips {

					trip_config {
						temperature = <0x1e848>;
						hysteresis = <0x3e8>;
						type = "passive";
					};
				};
			};

			cp_on_chip_4 {
				polling-delay-passive = <0x00>;
				polling-delay = <0x00>;
				thermal-governor = "user_space";
				thermal-sensors = <0xffffffff 0x04>;

				trips {

					trip_config {
						temperature = <0x1e848>;
						hysteresis = <0x3e8>;
						type = "passive";
					};
				};
			};

			cp_on_chip_5 {
				polling-delay-passive = <0x00>;
				polling-delay = <0x00>;
				thermal-governor = "user_space";
				thermal-sensors = <0xffffffff 0x05>;

				trips {

					trip_config {
						temperature = <0x1e848>;
						hysteresis = <0x3e8>;
						type = "passive";
					};
				};
			};

			cp_on_chip_6 {
				polling-delay-passive = <0x00>;
				polling-delay = <0x00>;
				thermal-governor = "user_space";
				thermal-sensors = <0xffffffff 0x06>;

				trips {

					trip_config {
						temperature = <0x1e848>;
						hysteresis = <0x3e8>;
						type = "passive";
					};
				};
			};

			rf2_therm {
				polling-delay-passive = <0x00>;
				polling-delay = <0x00>;
				thermal-governor = "user_space";
				thermal-sensors = <0xffffffff 0x07>;

				trips {

					trip_config {
						temperature = <0x1e848>;
						hysteresis = <0x3e8>;
						type = "passive";
					};
				};
			};

			rf1_therm {
				polling-delay-passive = <0x00>;
				polling-delay = <0x00>;
				thermal-governor = "user_space";
				thermal-sensors = <0xffffffff 0x08>;

				trips {

					trip_config {
						temperature = <0x1e848>;
						hysteresis = <0x3e8>;
						type = "passive";
					};
				};
			};
		};
	};

	fragment@43 {
		target = <0xffffffff>;

		__overlay__ {

			s5100_cp2ap_cp_ps_hold {
				samsung,pins = "gpa9-5";
				samsung,pin-function = <0x0f>;
				samsung,pin-pud = <0x00>;
				phandle = <0x42>;
			};
		};
	};

	fragment@44 {
		target = <0xffffffff>;

		__overlay__ {

			s5100_cp2ap_wakeup {
				samsung,pins = "gpa8-4";
				samsung,pin-function = <0x0f>;
				samsung,pin-pud = <0x00>;
				phandle = <0x44>;
			};
		};
	};

	fragment@45 {
		target = <0xffffffff>;

		__overlay__ {

			s5100_ap2cp_cp_nreset_n {
				samsung,pins = "gph1-3";
				samsung,pin-pud = <0x00>;
				samsung,pin-con-pdn = <0x03>;
				samsung,pin-pud-pdn = <0x00>;
				phandle = <0x41>;
			};

			s5100_ap2cp_cp_pwr_on {
				samsung,pins = "gph1-0";
				samsung,pin-pud = <0x00>;
				samsung,pin-con-pdn = <0x03>;
				samsung,pin-pud-pdn = <0x00>;
				phandle = <0x40>;
			};

			s5100_ap2cp_pda_active {
				samsung,pins = "gph1-1";
				samsung,pin-pud = <0x00>;
				samsung,pin-con-pdn = <0x03>;
				samsung,pin-pud-pdn = <0x00>;
				phandle = <0x46>;
			};

			s5100_ap2cp_wakeup {
				samsung,pins = "gph0-2";
				samsung,pin-pud = <0x00>;
				samsung,pin-con-pdn = <0x03>;
				samsung,pin-pud-pdn = <0x00>;
				phandle = <0x43>;
			};

			s5100_ap2cp_dump_noti {
				samsung,pins = "gph0-3";
				samsung,pin-pud = <0x00>;
				samsung,pin-con-pdn = <0x03>;
				samsung,pin-pud-pdn = <0x00>;
				phandle = <0x45>;
			};
		};
	};

	fragment@46 {
		target = <0xffffffff>;

		__overlay__ {
			status = "ok";
			#address-cells = <0x01>;
			#size-cells = <0x00>;

			panel@0 {
				compatible = "samsung,s6e3hc2-fhd";
				label = "samsung-s6e3hc2-fhd";
				channel = <0x00>;
				touch = <0x48>;
				reset-gpios = <0xffffffff 0x01 0x00>;
				vci-supply = <0x49>;
				vddi-supply = <0x4a>;
			};

			panel@1 {
				compatible = "samsung,emul";
				label = "samsung-emul";
				channel = <0x00>;
				reset-gpios = <0xffffffff 0x01 0x00>;
			};
		};
	};

	fragment@47 {
		target = <0xffffffff>;

		__overlay__ {
			status = "disabled";
		};
	};

	fragment@48 {
		target = <0xffffffff>;

		__overlay__ {

			nfc-rst {
				samsung,pins = "gpp24-2";
				samsung,pin-pud-pdn = <0x03>;
				phandle = <0x4b>;
			};

			nfc-pidle {
				samsung,pins = "gpp26-2";
				samsung,pin-pud = <0x03>;
				samsung,pin-pud-pdn = <0x03>;
				samsung,pin-con-pdn = <0x03>;
				phandle = <0x4c>;
			};
		};
	};

	fragment@49 {
		target = <0xffffffff>;

		__overlay__ {
			samsung,pin-con-pdn = <0x03>;
			samsung,pin-pud-pdn = <0x00>;
		};
	};

	fragment@50 {
		target = <0xffffffff>;

		__overlay__ {
			#address-cells = <0x01>;
			#size-cells = <0x00>;
			clock-frequency = <0x5a550>;
			status = "okay";

			st21nfc@08 {
				compatible = "st,st21nfc";
				reg = <0x08>;
				pinctrl-names = "default";
				pinctrl-0 = <0x4b 0x4c>;
				interrupt-parent = <0xffffffff>;
				interrupts = <0x00 0x00 0x00>;
				reset-gpios = <0xffffffff 0x02 0x00>;
				irq-gpios = <0xffffffff 0x00 0x00>;
				clkreq-gpios = <0xffffffff 0x04 0x00>;
				pidle-gpios = <0xffffffff 0x02 0x00>;
				st,pidle_active_low;
				clock-names = "nfc_ref_clk";
				clocks = <0xffffffff 0x60f>;
				pmu_clk_pad = <0x3e80>;
				status = "ok";
			};
		};
	};

	fragment@51 {
		target = <0xffffffff>;

		__overlay__ {
			max-link-speed = <0x01>;
		};
	};

	fragment@52 {
		target = <0xffffffff>;

		__overlay__ {

			sec_ts-irq {
				samsung,pins = "gpa9-0";
				samsung,pin-pud = <0x00>;
				samsung,pin-drv = <0x00>;
				phandle = <0x4f>;
			};
		};
	};

	fragment@53 {
		target = <0xffffffff>;

		__overlay__ {

			sec_ts-reset {
				samsung,pins = "gpp26-0";
				samsung,pin-pud = <0x00>;
				phandle = <0x50>;
			};

			sec_ts-switch {
				samsung,pins = "gpp26-1";
				samsung,pin-pud = <0x00>;
				phandle = <0x51>;
			};

			spi11-bus {
				samsung,pins = "gpp23-0\0gpp23-1\0gpp23-2";
				samsung,pin-function = <0x02>;
				samsung,pin-pud = <0x00>;
				samsung,pin-drv = <0x01>;
				phandle = <0x4d>;
			};

			spi11-cs {
				samsung,pins = "gpp23-3";
				samsung,pin-function = <0x01>;
				samsung,pin-pud = <0x00>;
				samsung,pin-drv = <0x01>;
				phandle = <0xc2>;
			};

			spi11-cs-func {
				samsung,pins = "gpp23-3";
				samsung,pin-function = <0x02>;
				samsung,pin-pud = <0x00>;
				samsung,pin-drv = <0x01>;
				phandle = <0x4e>;
			};
		};
	};

	fragment@54 {
		target = <0xffffffff>;

		__overlay__ {
			#address-cells = <0x01>;
			#size-cells = <0x00>;
			status = "okay";
			pinctrl-names = "default";
			pinctrl-0 = <0x4d 0x4e>;

			touchscreen@0 {
				status = "ok";
				compatible = "sec,sec_ts";
				spi-max-frequency = <0xf42400>;
				spi-cpol;
				spi-cpha;
				reg = <0x00>;
				pinctrl-names = "default";
				pinctrl-0 = <0x4f 0x50 0x51>;
				sec,irq_gpio = <0xffffffff 0x00 0x00>;
				sec,switch_gpio = <0xffffffff 0x01 0x00>;
				sec,reset_gpio = <0xffffffff 0x00 0x00>;
				sec,firmware_name = "s6sy79x.bin";
				sec,mis_cal_check = <0x01>;
				sec,heatmap_mode = <0x01>;
				sec,max_coords = <0x438 0x924>;
				vdd-supply = <0x52>;
				avdd-supply = <0x53>;
				phandle = <0x48>;

				controller-data {
					samsung,spi-feedback-delay = <0x00>;
					samsung,spi-chip-select-mode = <0x01>;
				};
			};
		};
	};

	fragment@55 {
		target = <0xffffffff>;

		__overlay__ {

			gsa_gsc@0 {
				compatible = "google,gs101-gsa-gsc-v1";
				interrupt-parent = <0xffffffff>;
				interrupts = <0x05 0x00 0x00>;
				gsc,ctdl_ap_irq = <0xffffffff 0x01 0x00>;
			};
		};
	};

	fragment@56 {
		target = <0xffffffff>;

		__overlay__ {

			bcm4775@0 {
				host-req-gpios = <0xffffffff 0x04 0x00>;
				mcu-resp-gpios = <0xffffffff 0x00 0x00>;
			};
		};
	};

	fragment@57 {
		target = <0xffffffff>;

		__overlay__ {

			gps-host-req {
				samsung,pins = "gpa6-4";
				samsung,pin-function = <0x0f>;
				samsung,pin-pud = <0x00>;
				samsung,pin-con-pdn = <0x03>;
				samsung,pin-pud-pdn = <0x00>;
				phandle = <0x04>;
			};
		};
	};

	fragment@58 {
		target = <0xffffffff>;

		__overlay__ {

			gps-mcu-resp {
				samsung,pins = "gpp0-0";
				samsung,pin-function = <0x00>;
				samsung,pin-pud = <0x01>;
				samsung,pin-con-pdn = <0x03>;
				samsung,pin-pud-pdn = <0x01>;
				phandle = <0x06>;
			};
		};
	};

	fragment@59 {
		target = <0xffffffff>;

		__overlay__ {

			if-pmic-fg-irq {
				samsung,pins = "gpa9-3";
				samsung,pin-function = <0x0f>;
				samsung,pin-pud = <0x03>;
				samsung,pin-drv = <0x00>;
				phandle = <0x55>;
			};
		};
	};

	fragment@60 {
		target = <0xffffffff>;

		__overlay__ {

			if-pmic-irq {
				samsung,pins = "gpa8-3";
				samsung,pin-function = <0x0f>;
				samsung,pin-pud = <0x03>;
				samsung,pin-drv = <0x00>;
				phandle = <0x54>;
			};
		};
	};

	fragment@61 {
		target = <0xffffffff>;

		__overlay__ {
			#address-cells = <0x01>;
			#size-cells = <0x00>;
			status = "okay";
			clock-frequency = <0x61a80>;

			max77729pmic@0x66 {
				status = "okay";
				compatible = "maxim,max77729pmic";
				reg = <0x66>;
				pinctrl-names = "default";
				pinctrl-0 = <0x54>;
				max777x9,irq-gpio = <0xffffffff 0x03 0x01>;
				max77759,max_m5 = <0x3f>;
				max20339,ovp = <0x0f>;
				phandle = <0x56>;

				max777x9_gpio {
					gpio-controller;
					#gpio-cells = <0x02>;
					ngpios = <0x06>;
					phandle = <0x0d>;
				};
			};

			max77759fg@0x36 {
				status = "okay";
				compatible = "maxim,max77759";
				reg = <0x36>;
				pinctrl-names = "default";
				pinctrl-0 = <0x55>;
				maxim,irq-gpio = <0xffffffff 0x03 0x01>;
				maxim,rsense-default = <0x1f4>;
				maxim,batt-id-range-pct = <0x00>;
				maxim,psy-type-unknown;
				phandle = <0x3f>;
			};

			max77759chrg@0x69 {
				status = "okay";
				compatible = "maxim,max77759chrg";
				reg = <0x69>;
				#thermal-sensor-cells = <0x01>;
				interrupt-parent = <0xffffffff>;
				max77759,irq-gpio = <0xffffffff 0x03 0x01>;
				max77759,psy-name = "main-charger";
				max77759,max_m5 = <0x3f>;
				max77759,pmic = <0x56>;
				max77759,bst-on = <0x0d 0x04 0x00>;
				max77759,bst-sel = <0xffffffff 0x03 0x00>;
				max77759,extbst-ctl = <0x57 0x00 0x00>;
				max77759,lsw1-is_open = <0x0e 0x05 0x00>;
				max77759,lsw1-is_closed = <0x0e 0x06 0x00>;
				max77759,vin-is_valid = <0x0e 0x03 0x00>;
				phandle = <0x3e>;
			};
		};
	};

	fragment@62 {
		target = <0xffffffff>;

		__overlay__ {

			s5100_cp2ap_phone_active {
				samsung,pins = "gpa8-5";
				samsung,pin-function = <0x0f>;
				samsung,pin-pud = <0x00>;
				samsung,pin-con-pdn = <0x03>;
				phandle = <0x47>;
			};
		};
	};

	fragment@63 {
		target = <0xffffffff>;

		__overlay__ {

			s2mpg11mfd@00 {

				gs101_spmic_tm1 {
					compatible = "google,gs101-spmic-thermal";
					#thermal-sensor-cells = <0x01>;
					adc_chan_en = [20];
					phandle = <0x58>;
				};
			};
		};
	};

	fragment@64 {
		target = <0xffffffff>;

		__overlay__ {

			soc_therm {
				polling-delay-passive = <0x00>;
				polling-delay = <0x00>;
				thermal-governor = "user_space";
				thermal-sensors = <0x58 0x00>;

				trips {

					trip-config0 {
						temperature = <0x1e848>;
						hysteresis = <0x3e8>;
						type = "passive";
						phandle = <0xc3>;
					};
				};
			};

			quiet_therm {
				polling-delay-passive = <0x00>;
				polling-delay = <0x00>;
				thermal-governor = "user_space";
				thermal-sensors = <0x58 0x01>;

				trips {

					trip-config1 {
						temperature = <0x1e848>;
						hysteresis = <0x3e8>;
						type = "passive";
						phandle = <0xc4>;
					};
				};
			};

			qi_therm {
				polling-delay-passive = <0x00>;
				polling-delay = <0x00>;
				thermal-governor = "user_space";
				thermal-sensors = <0x58 0x02>;

				trips {

					trip-config2 {
						temperature = <0x1e848>;
						hysteresis = <0x3e8>;
						type = "passive";
						phandle = <0xc5>;
					};
				};
			};

			therm_3 {
				polling-delay-passive = <0x00>;
				polling-delay = <0x00>;
				thermal-governor = "user_space";
				thermal-sensors = <0x58 0x03>;

				trips {

					trip-config3 {
						temperature = <0x1e848>;
						hysteresis = <0x3e8>;
						type = "passive";
						phandle = <0xc6>;
					};
				};
			};

			therm_4 {
				polling-delay-passive = <0x00>;
				polling-delay = <0x00>;
				thermal-governor = "user_space";
				thermal-sensors = <0x58 0x04>;

				trips {

					trip-config4 {
						temperature = <0x1e848>;
						hysteresis = <0x3e8>;
						type = "passive";
						phandle = <0xc7>;
					};
				};
			};

			disp_therm {
				polling-delay-passive = <0x1388>;
				polling-delay = <0x7530>;
				thermal-governor = "step_wise";
				thermal-sensors = <0x58 0x05>;

				trips {

					skin-critical {
						temperature = <0x9c40>;
						hysteresis = <0x3e8>;
						type = "passive";
						phandle = <0x59>;
					};

					skin-sw-shutdown {
						temperature = <0xc350>;
						hysteresis = <0x3e8>;
						type = "critical";
						phandle = <0xc8>;
					};

					skin-hw-shutdown {
						temperature = <0x13880>;
						hysteresis = <0x3e8>;
						type = "hot";
						phandle = <0xc9>;
					};
				};

				cooling-maps {

					cpu0-map {
						trip = <0x59>;
						cooling-device = <0xffffffff 0xffffffff 0xffffffff>;
					};

					cpu1-map {
						trip = <0x59>;
						cooling-device = <0xffffffff 0xffffffff 0xffffffff>;
					};

					cpu2-map {
						trip = <0x59>;
						cooling-device = <0xffffffff 0xffffffff 0xffffffff>;
					};

					gpu-map {
						trip = <0x59>;
						cooling-device = <0xffffffff 0xffffffff 0xffffffff>;
					};
				};
			};

			ufs_stb_therm {
				polling-delay-passive = <0x00>;
				polling-delay = <0x00>;
				thermal-governor = "user_space";
				thermal-sensors = <0x58 0x06>;

				trips {

					trip-config6 {
						temperature = <0x1e848>;
						hysteresis = <0x3e8>;
						type = "passive";
						phandle = <0xca>;
					};
				};
			};

			gnss_tcxo_therm {
				polling-delay-passive = <0x00>;
				polling-delay = <0x00>;
				thermal-governor = "user_space";
				thermal-sensors = <0x58 0x07>;

				trips {

					trip-config7 {
						temperature = <0x1e848>;
						hysteresis = <0x3e8>;
						type = "passive";
						phandle = <0xcb>;
					};
				};
			};
		};
	};

	fragment@65 {
		target = <0xffffffff>;

		__overlay__ {

			soc {
				zone_name = "BATT_SOC_MOD";
				polling-delay-passive = <0x00>;
				polling-delay = <0x00>;
				thermal-sensors = <0x5a 0x09>;

				trips {

					soc-trip {
						temperature = <0x50>;
						hysteresis = <0x00>;
						type = "passive";
						phandle = <0xcc>;
					};
				};
			};

			vdroop1 {
				zone_name = "VDROOP1";
				polling-delay-passive = <0x00>;
				polling-delay = <0x00>;
				thermal-sensors = <0x5a 0x0a>;

				trips {

					vdroop1 {
						temperature = <0x3e8>;
						hysteresis = <0x64>;
						type = "passive";
						phandle = <0xcd>;
					};
				};
			};

			vdroop2 {
				zone_name = "VDROOP2";
				polling-delay-passive = <0x00>;
				polling-delay = <0x00>;
				thermal-sensors = <0x5a 0x0b>;

				trips {

					vdroop2 {
						temperature = <0x4b0>;
						hysteresis = <0x64>;
						type = "passive";
						phandle = <0xce>;
					};
				};
			};

			batoilo {
				zone_name = "BATOILO";
				polling-delay-passive = <0x00>;
				polling-delay = <0x00>;
				thermal-sensors = <0x5a 0x0c>;

				trips {

					batoilo {
						temperature = <0x1388>;
						hysteresis = <0x64>;
						type = "passive";
						phandle = <0xcf>;
					};
				};
			};

			pmic_120c {
				zone_name = "PMIC_120C";
				polling-delay-passive = <0x3e8>;
				polling-delay = <0x00>;
				thermal-sensors = <0x5a 0x0d>;

				trips {

					pmic-120c {
						temperature = <0x4b0>;
						hysteresis = <0x64>;
						type = "passive";
						phandle = <0xd0>;
					};
				};
			};

			pmic_140c {
				zone_name = "PMIC_140C";
				polling-delay-passive = <0x3e8>;
				polling-delay = <0x00>;
				thermal-sensors = <0x5a 0x0e>;

				trips {

					pmic-140c {
						temperature = <0x578>;
						hysteresis = <0x64>;
						type = "passive";
						phandle = <0xd1>;
					};
				};
			};

			pmic_overheat {
				zone_name = "PMIC_OVERHEAT";
				polling-delay-passive = <0x3e8>;
				polling-delay = <0x00>;
				thermal-sensors = <0x5a 0x0f>;

				trips {

					pmic-overheat {
						temperature = <0x7d0>;
						hysteresis = <0x64>;
						type = "passive";
						phandle = <0xd2>;
					};
				};
			};

			battery_cycle {
				zone_name = "BATTERY_CYCLE";
				polling-delay-passive = <0x64>;
				polling-delay = <0x00>;
				thermal-sensors = <0x5b>;
			};

			smpl_gm {
				zone_name = "SMPL_GM";
				polling-delay-passive = <0x64>;
				polling-delay = <0x00>;
				thermal-sensors = <0x5a 0x00>;

				trips {

					smpl_0 {
						temperature = <0x44c>;
						hysteresis = <0x64>;
						type = "passive";
						phandle = <0xd3>;
					};
				};
			};

			ocp_cpu1 {
				zone_name = "OCP_CPU1";
				polling-delay-passive = <0x64>;
				polling-delay = <0x00>;
				thermal-sensors = <0x5a 0x01>;

				trips {

					ocp-cpu1 {
						temperature = <0x1b58>;
						hysteresis = <0x64>;
						type = "passive";
						phandle = <0xd4>;
					};
				};
			};

			ocp_cpu2 {
				zone_name = "OCP_CPU2";
				polling-delay-passive = <0x64>;
				polling-delay = <0x00>;
				thermal-sensors = <0x5a 0x02>;

				trips {

					ocp-cpu2 {
						temperature = <0x2ee0>;
						hysteresis = <0x64>;
						type = "passive";
						phandle = <0xd5>;
					};
				};
			};

			soft_ocp_cpu1 {
				zone_name = "SOFT_OCP_CPU1";
				polling-delay-passive = <0x64>;
				polling-delay = <0x00>;
				thermal-sensors = <0x5a 0x03>;

				trips {

					soft-ocp-cpu1 {
						temperature = <0x1b58>;
						hysteresis = <0x64>;
						type = "passive";
						phandle = <0xd6>;
					};
				};
			};

			soft_ocp_cpu2 {
				zone_name = "SOFT_OCP_CPU2";
				polling-delay-passive = <0x64>;
				polling-delay = <0x00>;
				thermal-sensors = <0x5a 0x04>;

				trips {

					soft-ocp-cpu2 {
						temperature = <0x2328>;
						hysteresis = <0x64>;
						type = "passive";
						phandle = <0xd7>;
					};
				};
			};

			ocp_tpu {
				zone_name = "OCP_TPU";
				polling-delay-passive = <0x64>;
				polling-delay = <0x00>;
				thermal-sensors = <0x5a 0x05>;

				trips {

					ocp-tpu {
						temperature = <0x2904>;
						hysteresis = <0x64>;
						type = "passive";
						phandle = <0xd8>;
					};
				};
			};

			soft_ocp_tpu {
				zone_name = "SOFT_OCP_TPU";
				polling-delay-passive = <0x64>;
				polling-delay = <0x00>;
				thermal-sensors = <0x5a 0x06>;

				trips {

					soft-ocp-tpu {
						temperature = <0x2134>;
						hysteresis = <0x64>;
						type = "passive";
						phandle = <0xd9>;
					};
				};
			};

			ocp_gpu {
				zone_name = "OCP_GPU";
				polling-delay-passive = <0x64>;
				polling-delay = <0x00>;
				thermal-sensors = <0x5a 0x07>;

				trips {

					ocp-gpu {
						temperature = <0x2ee0>;
						hysteresis = <0x64>;
						type = "passive";
						phandle = <0xda>;
					};
				};
			};

			soft_ocp_gpu {
				zone_name = "SOFT_OCP_GPU";
				polling-delay-passive = <0x64>;
				polling-delay = <0x00>;
				thermal-sensors = <0x5a 0x08>;

				trips {

					soft-ocp-gpu {
						temperature = <0x2328>;
						hysteresis = <0x64>;
						type = "passive";
						phandle = <0xdb>;
					};
				};
			};
		};
	};

	fragment@wlc {
		target-path = "/";

		__overlay__ {

			google,charger {
				google,wlc-power-supply = "wireless";
			};
		};
	};

	fragment@66 {
		target = <0xffffffff>;

		__overlay__ {

			wc_irq {
				samsung,pins = "gpa9-7";
				samsung,pin-function = <0x0f>;
				samsung,pin-pud = <0x03>;
				samsung,pin-drv = <0x00>;
				phandle = <0x5c>;
			};
		};
	};

	fragment@67 {
		target = <0xffffffff>;

		__overlay__ {

			wc_ref {
				samsung,pins = "gpp1-3";
				samsung,pin-function = <0x01>;
				samsung,pin-pud = <0x01>;
				samsung,pin-drv = <0x00>;
				phandle = <0x5d>;
			};
		};
	};

	fragment@68 {
		target = <0xffffffff>;

		__overlay__ {

			wc_en {
				samsung,pins = "gpp27-3";
				samsung,pin-function = <0x01>;
				samsung,pin-pud = <0x00>;
				samsung,pin-con-pdn = <0x03>;
				samsung,pin-pud-pdn = <0x00>;
				phandle = <0x5e>;
			};
		};
	};

	fragment@69 {
		target = <0xffffffff>;

		__overlay__ {
			#address-cells = <0x01>;
			#size-cells = <0x00>;
			status = "ok";

			p9412@3c {
				status = "ok";
				compatible = "idt,p9412";
				reg = <0x3c>;
				pinctrl-names = "default";
				pinctrl-0 = <0x5c 0x5d 0x5e>;
				interrupt-names = "p9382_int";
				idt,irq_gpio = <0xffffffff 0x07 0x01>;
				idt,has_wlc_dc = <0x00>;
			};
		};
	};

	fragment@70 {
		target = <0xffffffff>;

		__overlay__ {

			codec {
				sound-dai = <0x5f 0x00 0x60 0x00>;
			};
		};
	};

	fragment@71 {
		target = <0xffffffff>;

		__overlay__ {

			codec {
				sound-dai = <0x5f 0x00 0x60 0x00>;
			};
		};
	};

	fragment@72 {
		target = <0xffffffff>;

		__overlay__ {

			clks {

				sys {

					sys@cs35l41_l {
						comp = <0x5f>;
						src = "BCLK";
						id = <0x00>;
						srcid = <0x00>;
						in_mul = <0x01>;
						out_mul = <0x01>;
					};

					sys@cs35l41_r {
						comp = <0x60>;
						src = "BCLK";
						id = <0x00>;
						srcid = <0x00>;
						in_mul = <0x01>;
						out_mul = <0x01>;
					};
				};
			};
		};
	};

	fragment@73 {
		target = <0xffffffff>;

		__overlay__ {

			cs35l41-r-irq {
				samsung,pins = "gpa9-6";
				samsung,pin-function = <0x0f>;
				samsung,pin-pud = <0x00>;
				phandle = <0x66>;
			};
		};
	};

	fragment@74 {
		target = <0xffffffff>;

		__overlay__ {

			cs35l41-l-irq {
				samsung,pins = "gpa6-3";
				samsung,pin-function = <0x0f>;
				samsung,pin-pud = <0x00>;
				phandle = <0x63>;
			};
		};
	};

	fragment@75 {
		target = <0xffffffff>;

		__overlay__ {

			cs35l41-l-rst {
				samsung,pins = "gpp16-3";
				samsung,pin-function = <0x01>;
				samsung,pin-pud = <0x00>;
				samsung,pin-con-pdn = <0x03>;
				samsung,pin-pud-pdn = <0x00>;
				phandle = <0x62>;
			};
		};
	};

	fragment@76 {
		target = <0xffffffff>;

		__overlay__ {

			cs35l41-r-rst {
				samsung,pins = "gpp23-7";
				samsung,pin-function = <0x01>;
				samsung,pin-pud = <0x00>;
				samsung,pin-con-pdn = <0x03>;
				samsung,pin-pud-pdn = <0x00>;
				phandle = <0x65>;
			};

			hapt-amp-rst {
				samsung,pins = "gpp24-0";
				samsung,pin-function = <0x01>;
				samsung,pin-pud = <0x00>;
				samsung,pin-con-pdn = <0x03>;
				samsung,pin-pud-pdn = <0x00>;
				phandle = <0x61>;
			};

			hapt-amp-trig {
				samsung,pins = "gpp24-3";
				samsung,pin-function = <0x01>;
				samsung,pin-pud = <0x00>;
				samsung,pin-con-pdn = <0x03>;
				samsung,pin-pud-pdn = <0x00>;
				phandle = <0xdc>;
			};
		};
	};

	fragment@77 {
		target = <0xffffffff>;

		__overlay__ {
			#address-cells = <0x01>;
			#size-cells = <0x00>;
			status = "okay";
			pinctrl-names = "default";
			pinctrl-0 = <0xffffffff>;
			clock-frequency = <0x61a80>;

			drv2624_haptics@5a {
				compatible = "ti,drv2624";
				reg = <0x5a>;
				pinctrl-names = "default";
				pinctrl-0 = <0x61>;
				ti,reset-gpio = <0xffffffff 0x00 0x00>;
				ti,smart-loop = <0x00>;
				ti,actuator = <0x01>;
				ti,rated-voltage = <0x4d>;
				ti,odclamp-voltage = <0xa5>;
				ti,lra-frequency = <0x9b>;
				ti,ol-lra-frequency = <0x9b>;
				ti,bemf-factor = <0xbc>;
				ti,bemf-gain = <0x01>;
				ti,voltage-comp = <0x09>;
				ti,blanking-time = <0x02>;
				ti,idiss-time = <0x02>;
				ti,zc-det-time = <0x00>;
				ti,lra-wave-shape = <0x00>;
				ti,waveform-interval = <0x01>;
				status = "okay";
			};

			cs35l41@40 {
				compatible = "cirrus,cs35l41";
				#sound-dai-cells = <0x01>;
				reg = <0x40>;
				pinctrl-names = "default";
				pinctrl-0 = <0x62 0x63>;
				interrupt-parent = <0xffffffff>;
				interrupts = <0x03 0x00 0x00>;
				reset-gpios = <0xffffffff 0x03 0x00>;
				VA-supply = <0x64>;
				VP-supply = <0xffffffff>;
				cirrus,boost-peak-milliamp = <0xdac>;
				cirrus,boost-ind-nanohenry = <0x3e8>;
				cirrus,boost-cap-microfarad = <0x1e>;
				cirrus,asp-sdout-hiz = <0x03>;
				cirrus,tuning-has-prefix;
				cirrus,left-channel-amp;
				phandle = <0x5f>;

				cirrus,gpio-config2 {
					cirrus,gpio-src-select = <0x05>;
					cirrus,gpio-output-enable;
				};
			};

			cs35l41@41 {
				compatible = "cirrus,cs35l41";
				#sound-dai-cells = <0x01>;
				sound-name-prefix = "R";
				reg = <0x41>;
				pinctrl-names = "default";
				pinctrl-0 = <0x65 0x66>;
				interrupt-parent = <0xffffffff>;
				interrupts = <0x06 0x00 0x00>;
				reset-gpios = <0xffffffff 0x07 0x00>;
				VA-supply = <0x64>;
				VP-supply = <0xffffffff>;
				cirrus,boost-peak-milliamp = <0xdac>;
				cirrus,boost-ind-nanohenry = <0x3e8>;
				cirrus,boost-cap-microfarad = <0x1e>;
				cirrus,asp-sdout-hiz = <0x03>;
				cirrus,tuning-has-prefix;
				cirrus,left-channel-amp;
				phandle = <0x60>;

				cirrus,gpio-config2 {
					cirrus,gpio-src-select = <0x05>;
					cirrus,gpio-output-enable;
				};
			};
		};
	};

	fragment@78 {
		target = <0xffffffff>;

		__overlay__ {
			aoc-board-cfg = "wf2";
			aoc-board-id = <0x201>;
			aoc-board-rev = <0x201>;
		};
	};

	fragment@boardbase {
		target-path = "/";

		__overlay__ {
			model = "GS101 WHITEFIN2 based on GS101";
			compatible = "google,GS101 WHITEFIN2\0google,GS101";
		};
	};

	__symbols__ {
		bt_reg_on = "/fragment@0/__overlay__/bt-reg-on";
		bt_dev_wake = "/fragment@0/__overlay__/bt-dev-wake";
		bt_host_wake = "/fragment@1/__overlay__/bt-host-wake";
		btbcm = "/fragment@3/__overlay__/btbcm";
		gps_mcu_req = "/fragment@5/__overlay__/gps-mcu-req";
		gps_nstandby = "/fragment@5/__overlay__/gps-nstandby";
		fusb307b = "/fragment@6/__overlay__/fusb307b@50";
		usb_con = "/fragment@6/__overlay__/fusb307b@50/connector";
		mux_notification_source = "/fragment@6/__overlay__/fusb307b@50/connector/port/endpoint@0";
		mux_notification_sink = "/fragment@6/__overlay__/fusb307b@50/port/endpoint@0";
		slg_pld = "/fragment@6/__overlay__/slg46826@8";
		max20339_ovp = "/fragment@6/__overlay__/max20339ovp@35";
		max20339_gpio = "/fragment@6/__overlay__/max20339ovp@35/max20339_gpio";
		max77759tcpc = "/fragment@6/__overlay__/max77759tcpc@25";
		conn = "/fragment@6/__overlay__/max77759tcpc@25/connector";
		mux_notification_src = "/fragment@6/__overlay__/max77759tcpc@25/connector/port/endpoint@0";
		mux_notification_snk = "/fragment@6/__overlay__/max77759tcpc@25/port/endpoint@0";
		max77759_tcpc_gpio = "/fragment@6/__overlay__/max77759tcpc@25/max77759_tcpc_gpio";
		usb_pd_irq = "/fragment@8/__overlay__/usb-pd-irq";
		cfg_wlanen = "/fragment@9/__overlay__/cfg_wlanen";
		wlan_host_wake = "/fragment@10/__overlay__/wlan_host_wake";
		wlan_dev_wake = "/fragment@11/__overlay__/wlan_dev_wake";
		m_pmic_irq = "/fragment@13/__overlay__/m-pmic-irq";
		s_pmic_irq = "/fragment@13/__overlay__/s-pmic-irq";
		smpl_warn = "/fragment@13/__overlay__/smpl-warn";
		s2mpg10mfd = "/fragment@14/__overlay__/s2mpg10mfd@00";
		m_buck1_reg = "/fragment@14/__overlay__/s2mpg10mfd@00/regulators/BUCK1M";
		m_buck2_reg = "/fragment@14/__overlay__/s2mpg10mfd@00/regulators/BUCK2M";
		m_buck3_reg = "/fragment@14/__overlay__/s2mpg10mfd@00/regulators/BUCK3M";
		m_buck4_reg = "/fragment@14/__overlay__/s2mpg10mfd@00/regulators/BUCK4M";
		m_buck5_reg = "/fragment@14/__overlay__/s2mpg10mfd@00/regulators/BUCK5M";
		m_buck6_reg = "/fragment@14/__overlay__/s2mpg10mfd@00/regulators/BUCK6M";
		m_buck7_reg = "/fragment@14/__overlay__/s2mpg10mfd@00/regulators/BUCK7M";
		m_buck8_reg = "/fragment@14/__overlay__/s2mpg10mfd@00/regulators/BUCK8M";
		m_buck9_reg = "/fragment@14/__overlay__/s2mpg10mfd@00/regulators/BUCK9M";
		m_buck10_reg = "/fragment@14/__overlay__/s2mpg10mfd@00/regulators/BUCK10M";
		m_ldo1_reg = "/fragment@14/__overlay__/s2mpg10mfd@00/regulators/LDO1M";
		m_ldo2_reg = "/fragment@14/__overlay__/s2mpg10mfd@00/regulators/LDO2M";
		m_ldo3_reg = "/fragment@14/__overlay__/s2mpg10mfd@00/regulators/LDO3M";
		m_ldo4_reg = "/fragment@14/__overlay__/s2mpg10mfd@00/regulators/LDO4M";
		m_ldo5_reg = "/fragment@14/__overlay__/s2mpg10mfd@00/regulators/LDO5M";
		m_ldo6_reg = "/fragment@14/__overlay__/s2mpg10mfd@00/regulators/LDO6M";
		m_ldo7_reg = "/fragment@14/__overlay__/s2mpg10mfd@00/regulators/LDO7M";
		m_ldo8_reg = "/fragment@14/__overlay__/s2mpg10mfd@00/regulators/LDO8M";
		m_ldo9_reg = "/fragment@14/__overlay__/s2mpg10mfd@00/regulators/LDO9M";
		m_ldo10_reg = "/fragment@14/__overlay__/s2mpg10mfd@00/regulators/LDO10M";
		m_ldo11_reg = "/fragment@14/__overlay__/s2mpg10mfd@00/regulators/LDO11M";
		m_ldo12_reg = "/fragment@14/__overlay__/s2mpg10mfd@00/regulators/LDO12M";
		m_ldo13_reg = "/fragment@14/__overlay__/s2mpg10mfd@00/regulators/LDO13M";
		m_ldo14_reg = "/fragment@14/__overlay__/s2mpg10mfd@00/regulators/LDO14M";
		m_ldo15_reg = "/fragment@14/__overlay__/s2mpg10mfd@00/regulators/LDO15M";
		m_ldo16_reg = "/fragment@14/__overlay__/s2mpg10mfd@00/regulators/LDO16M";
		m_ldo17_reg = "/fragment@14/__overlay__/s2mpg10mfd@00/regulators/LDO17M";
		m_ldo18_reg = "/fragment@14/__overlay__/s2mpg10mfd@00/regulators/LDO18M";
		m_ldo19_reg = "/fragment@14/__overlay__/s2mpg10mfd@00/regulators/LDO19M";
		m_ldo20_reg = "/fragment@14/__overlay__/s2mpg10mfd@00/regulators/LDO20M";
		m_ldo21_reg = "/fragment@14/__overlay__/s2mpg10mfd@00/regulators/LDO21M";
		m_ldo22_reg = "/fragment@14/__overlay__/s2mpg10mfd@00/regulators/LDO22M";
		m_ldo23_reg = "/fragment@14/__overlay__/s2mpg10mfd@00/regulators/LDO23M";
		m_ldo24_reg = "/fragment@14/__overlay__/s2mpg10mfd@00/regulators/LDO24M";
		m_ldo25_reg = "/fragment@14/__overlay__/s2mpg10mfd@00/regulators/LDO25M";
		m_ldo26_reg = "/fragment@14/__overlay__/s2mpg10mfd@00/regulators/LDO26M";
		m_ldo27_reg = "/fragment@14/__overlay__/s2mpg10mfd@00/regulators/LDO27M";
		m_ldo28_reg = "/fragment@14/__overlay__/s2mpg10mfd@00/regulators/LDO28M";
		m_ldo29_reg = "/fragment@14/__overlay__/s2mpg10mfd@00/regulators/LDO29M";
		m_ldo30_reg = "/fragment@14/__overlay__/s2mpg10mfd@00/regulators/LDO30M";
		m_ldo31_reg = "/fragment@14/__overlay__/s2mpg10mfd@00/regulators/LDO31M";
		ch1 = "/fragment@14/__overlay__/s2mpg10mfd@00/odpm/channels/channel@0";
		ch2 = "/fragment@14/__overlay__/s2mpg10mfd@00/odpm/channels/channel@1";
		ch3 = "/fragment@14/__overlay__/s2mpg10mfd@00/odpm/channels/channel@2";
		ch4 = "/fragment@14/__overlay__/s2mpg10mfd@00/odpm/channels/channel@3";
		ch5 = "/fragment@14/__overlay__/s2mpg10mfd@00/odpm/channels/channel@4";
		ch6 = "/fragment@14/__overlay__/s2mpg10mfd@00/odpm/channels/channel@5";
		ch7 = "/fragment@14/__overlay__/s2mpg10mfd@00/odpm/channels/channel@6";
		ch8 = "/fragment@14/__overlay__/s2mpg10mfd@00/odpm/channels/channel@7";
		m_ext1_rail = "/fragment@14/__overlay__/s2mpg10mfd@00/odpm/rails/VSEN_C1";
		m_ext2_rail = "/fragment@14/__overlay__/s2mpg10mfd@00/odpm/rails/VSEN_C2";
		m_ext3_rail = "/fragment@14/__overlay__/s2mpg10mfd@00/odpm/rails/VSEN_C3";
		s2mpg10_gpio = "/fragment@14/__overlay__/s2mpg10mfd@00/s2mpg10_gpio";
		s2mpg10_pinctrl = "/fragment@14/__overlay__/s2mpg10mfd@00/s2mpg10_pinctrl";
		s2mpg11mfd = "/fragment@15/__overlay__/s2mpg11mfd@00";
		s_buck1_reg = "/fragment@15/__overlay__/s2mpg11mfd@00/regulators/BUCK1S";
		s_buck2_reg = "/fragment@15/__overlay__/s2mpg11mfd@00/regulators/BUCK2S";
		s_buck3_reg = "/fragment@15/__overlay__/s2mpg11mfd@00/regulators/BUCK3S";
		s_buck4_reg = "/fragment@15/__overlay__/s2mpg11mfd@00/regulators/BUCK4S";
		s_buck5_reg = "/fragment@15/__overlay__/s2mpg11mfd@00/regulators/BUCK5S";
		s_buck6_reg = "/fragment@15/__overlay__/s2mpg11mfd@00/regulators/BUCK6S";
		s_buck7_reg = "/fragment@15/__overlay__/s2mpg11mfd@00/regulators/BUCK7S";
		s_buck8_reg = "/fragment@15/__overlay__/s2mpg11mfd@00/regulators/BUCK8S";
		s_buck9_reg = "/fragment@15/__overlay__/s2mpg11mfd@00/regulators/BUCK9S";
		s_buck10_reg = "/fragment@15/__overlay__/s2mpg11mfd@00/regulators/BUCK10S";
		s_buckd_reg = "/fragment@15/__overlay__/s2mpg11mfd@00/regulators/BUCKD";
		s_bucka_reg = "/fragment@15/__overlay__/s2mpg11mfd@00/regulators/BUCKA";
		s_buckboost_reg = "/fragment@15/__overlay__/s2mpg11mfd@00/regulators/BUCKBOOST";
		s_ldo1_reg = "/fragment@15/__overlay__/s2mpg11mfd@00/regulators/LDO1S";
		s_ldo2_reg = "/fragment@15/__overlay__/s2mpg11mfd@00/regulators/LDO2S";
		s_ldo3_reg = "/fragment@15/__overlay__/s2mpg11mfd@00/regulators/LDO3S";
		s_ldo4_reg = "/fragment@15/__overlay__/s2mpg11mfd@00/regulators/LDO4S";
		s_ldo5_reg = "/fragment@15/__overlay__/s2mpg11mfd@00/regulators/LDO5S";
		s_ldo6_reg = "/fragment@15/__overlay__/s2mpg11mfd@00/regulators/LDO6S";
		s_ldo7_reg = "/fragment@15/__overlay__/s2mpg11mfd@00/regulators/LDO7S";
		s_ldo8_reg = "/fragment@15/__overlay__/s2mpg11mfd@00/regulators/LDO8S";
		s_ldo9_reg = "/fragment@15/__overlay__/s2mpg11mfd@00/regulators/LDO9S";
		s_ldo10_reg = "/fragment@15/__overlay__/s2mpg11mfd@00/regulators/LDO10S";
		s_ldo11_reg = "/fragment@15/__overlay__/s2mpg11mfd@00/regulators/LDO11S";
		s_ldo12_reg = "/fragment@15/__overlay__/s2mpg11mfd@00/regulators/LDO12S";
		s_ldo13_reg = "/fragment@15/__overlay__/s2mpg11mfd@00/regulators/LDO13S";
		s_ldo14_reg = "/fragment@15/__overlay__/s2mpg11mfd@00/regulators/LDO14S";
		s_ldo15_reg = "/fragment@15/__overlay__/s2mpg11mfd@00/regulators/LDO15S";
		ch9 = "/fragment@15/__overlay__/s2mpg11mfd@00/odpm/channels/channel@0";
		ch10 = "/fragment@15/__overlay__/s2mpg11mfd@00/odpm/channels/channel@1";
		ch11 = "/fragment@15/__overlay__/s2mpg11mfd@00/odpm/channels/channel@2";
		ch12 = "/fragment@15/__overlay__/s2mpg11mfd@00/odpm/channels/channel@3";
		ch13 = "/fragment@15/__overlay__/s2mpg11mfd@00/odpm/channels/channel@4";
		ch14 = "/fragment@15/__overlay__/s2mpg11mfd@00/odpm/channels/channel@5";
		ch15 = "/fragment@15/__overlay__/s2mpg11mfd@00/odpm/channels/channel@6";
		ch16 = "/fragment@15/__overlay__/s2mpg11mfd@00/odpm/channels/channel@7";
		s_ext4_rail = "/fragment@15/__overlay__/s2mpg11mfd@00/odpm/rails/VSEN_C4";
		s_ext5_rail = "/fragment@15/__overlay__/s2mpg11mfd@00/odpm/rails/VSEN_C5";
		s_ext6_rail = "/fragment@15/__overlay__/s2mpg11mfd@00/odpm/rails/VSEN_C6";
		s2mpg11_gpio = "/fragment@15/__overlay__/s2mpg11mfd@00/s2mpg11_gpio";
		s2mpg11_pinctrl = "/fragment@15/__overlay__/s2mpg11mfd@00/s2mpg11_pinctrl";
		key_voldown = "/fragment@18/__overlay__/key-voldown";
		key_volup = "/fragment@18/__overlay__/key-volup";
		key_power = "/fragment@19/__overlay__/key-power";
		usbdrd_dwc3 = "/fragment@21/__overlay__/dwc3";
		usb_hs_tune = "/fragment@22/__overlay__/hs_tune";
		usb_ss_tune = "/fragment@22/__overlay__/ss_tune";
		slg51000 = "/fragment@29/__overlay__/slg51000@75";
		slg51000_ldo1 = "/fragment@29/__overlay__/slg51000@75/regulators/ldo1";
		slg51000_ldo2 = "/fragment@29/__overlay__/slg51000@75/regulators/ldo2";
		slg51000_ldo3 = "/fragment@29/__overlay__/slg51000@75/regulators/ldo3";
		slg51000_ldo4 = "/fragment@29/__overlay__/slg51000@75/regulators/ldo4";
		slg51000_ldo5 = "/fragment@29/__overlay__/slg51000@75/regulators/ldo5";
		slg51000_ldo6 = "/fragment@29/__overlay__/slg51000@75/regulators/ldo6";
		slg51000_ldo7 = "/fragment@29/__overlay__/slg51000@75/regulators/ldo7";
		hsi2c2_bus = "/fragment@30/__overlay__/hsi2c2-bus";
		hsi2c2_bus_in = "/fragment@30/__overlay__/hsi2c2-bus-in";
		hsi2c3_bus = "/fragment@30/__overlay__/hsi2c3-bus";
		hsi2c3_bus_in = "/fragment@30/__overlay__/hsi2c3-bus-in";
		hsi2c4_bus = "/fragment@30/__overlay__/hsi2c4-bus";
		hsi2c4_bus_in = "/fragment@30/__overlay__/hsi2c4-bus-in";
		flash_active = "/fragment@31/__overlay__/flash_active";
		flash_suspend = "/fragment@31/__overlay__/flash_suspend";
		sensor0 = "/fragment@lwiscamera/__overlay__/sensor@0";
		sensor2 = "/fragment@lwiscamera/__overlay__/sensor@2";
		sensor1 = "/fragment@lwiscamera/__overlay__/sensor@1";
		actuator0 = "/fragment@lwiscamera/__overlay__/actuator@0";
		eeprom0 = "/fragment@lwiscamera/__overlay__/eeprom@0";
		eeprom1 = "/fragment@lwiscamera/__overlay__/eeprom@1";
		eeprom2 = "/fragment@lwiscamera/__overlay__/eeprom@2";
		flash0 = "/fragment@lwiscamera/__overlay__/flash@0";
		google_battery = "/fragment@battery/__overlay__/google,battery";
		google_cpm = "/fragment@battery/__overlay__/google,cpm";
		google_charger = "/fragment@battery/__overlay__/google,charger";
		google_mitigation = "/fragment@battery/__overlay__/google,mitigation";
		pack_bee = "/fragment@37/__overlay__/m24c08@50";
		s5100_cp2ap_cp_ps_hold = "/fragment@43/__overlay__/s5100_cp2ap_cp_ps_hold";
		s5100_cp2ap_wakeup = "/fragment@44/__overlay__/s5100_cp2ap_wakeup";
		s5100_ap2cp_cp_nreset_n = "/fragment@45/__overlay__/s5100_ap2cp_cp_nreset_n";
		s5100_ap2cp_cp_pwr_on = "/fragment@45/__overlay__/s5100_ap2cp_cp_pwr_on";
		s5100_ap2cp_pda_active = "/fragment@45/__overlay__/s5100_ap2cp_pda_active";
		s5100_ap2cp_wakeup = "/fragment@45/__overlay__/s5100_ap2cp_wakeup";
		s5100_ap2cp_dump_noti = "/fragment@45/__overlay__/s5100_ap2cp_dump_noti";
		nfc_rst = "/fragment@48/__overlay__/nfc-rst";
		nfc_pidle = "/fragment@48/__overlay__/nfc-pidle";
		sec_ts_irq = "/fragment@52/__overlay__/sec_ts-irq";
		sec_ts_reset = "/fragment@53/__overlay__/sec_ts-reset";
		sec_ts_switch = "/fragment@53/__overlay__/sec_ts-switch";
		spi11_bus = "/fragment@53/__overlay__/spi11-bus";
		spi11_cs = "/fragment@53/__overlay__/spi11-cs";
		spi11_cs_func = "/fragment@53/__overlay__/spi11-cs-func";
		spitouch = "/fragment@54/__overlay__/touchscreen@0";
		gps_host_req = "/fragment@57/__overlay__/gps-host-req";
		gps_mcu_resp = "/fragment@58/__overlay__/gps-mcu-resp";
		if_pmic_fg_irq = "/fragment@59/__overlay__/if-pmic-fg-irq";
		if_pmic_irq = "/fragment@60/__overlay__/if-pmic-irq";
		max77729_pmic = "/fragment@61/__overlay__/max77729pmic@0x66";
		max777x9_gpio = "/fragment@61/__overlay__/max77729pmic@0x66/max777x9_gpio";
		max77759_fg = "/fragment@61/__overlay__/max77759fg@0x36";
		max77759_chg = "/fragment@61/__overlay__/max77759chrg@0x69";
		s5100_cp2ap_phone_active = "/fragment@62/__overlay__/s5100_cp2ap_phone_active";
		gs101_tm1 = "/fragment@63/__overlay__/s2mpg11mfd@00/gs101_spmic_tm1";
		trip_config0 = "/fragment@64/__overlay__/soc_therm/trips/trip-config0";
		trip_config1 = "/fragment@64/__overlay__/quiet_therm/trips/trip-config1";
		trip_config2 = "/fragment@64/__overlay__/qi_therm/trips/trip-config2";
		trip_config3 = "/fragment@64/__overlay__/therm_3/trips/trip-config3";
		trip_config4 = "/fragment@64/__overlay__/therm_4/trips/trip-config4";
		skin_critical = "/fragment@64/__overlay__/disp_therm/trips/skin-critical";
		skin_sw_shutdown = "/fragment@64/__overlay__/disp_therm/trips/skin-sw-shutdown";
		skin_hw_shutdown = "/fragment@64/__overlay__/disp_therm/trips/skin-hw-shutdown";
		trip_config6 = "/fragment@64/__overlay__/ufs_stb_therm/trips/trip-config6";
		trip_config7 = "/fragment@64/__overlay__/gnss_tcxo_therm/trips/trip-config7";
		soc_trip = "/fragment@65/__overlay__/soc/trips/soc-trip";
		vdroop1 = "/fragment@65/__overlay__/vdroop1/trips/vdroop1";
		vdroop2 = "/fragment@65/__overlay__/vdroop2/trips/vdroop2";
		batoilo = "/fragment@65/__overlay__/batoilo/trips/batoilo";
		pmic_120c = "/fragment@65/__overlay__/pmic_120c/trips/pmic-120c";
		pmic_140c = "/fragment@65/__overlay__/pmic_140c/trips/pmic-140c";
		pmic_overheat = "/fragment@65/__overlay__/pmic_overheat/trips/pmic-overheat";
		smpl = "/fragment@65/__overlay__/smpl_gm/trips/smpl_0";
		ocp_cpu1 = "/fragment@65/__overlay__/ocp_cpu1/trips/ocp-cpu1";
		ocp_cpu2 = "/fragment@65/__overlay__/ocp_cpu2/trips/ocp-cpu2";
		soft_ocp_cpu1 = "/fragment@65/__overlay__/soft_ocp_cpu1/trips/soft-ocp-cpu1";
		soft_ocp_cpu2 = "/fragment@65/__overlay__/soft_ocp_cpu2/trips/soft-ocp-cpu2";
		ocp_tpu = "/fragment@65/__overlay__/ocp_tpu/trips/ocp-tpu";
		soft_ocp_tpu = "/fragment@65/__overlay__/soft_ocp_tpu/trips/soft-ocp-tpu";
		ocp_gpu = "/fragment@65/__overlay__/ocp_gpu/trips/ocp-gpu";
		soft_ocp_gpu = "/fragment@65/__overlay__/soft_ocp_gpu/trips/soft-ocp-gpu";
		wc_irq = "/fragment@66/__overlay__/wc_irq";
		wc_ref = "/fragment@67/__overlay__/wc_ref";
		wc_en = "/fragment@68/__overlay__/wc_en";
		cs35l41_r_irq = "/fragment@73/__overlay__/cs35l41-r-irq";
		cs35l41_l_irq = "/fragment@74/__overlay__/cs35l41-l-irq";
		cs35l41_l_rst = "/fragment@75/__overlay__/cs35l41-l-rst";
		cs35l41_r_rst = "/fragment@76/__overlay__/cs35l41-r-rst";
		hapt_amp_rst = "/fragment@76/__overlay__/hapt-amp-rst";
		hapt_amp_trig = "/fragment@76/__overlay__/hapt-amp-trig";
		cs35l41_l = "/fragment@77/__overlay__/cs35l41@40";
		cs35l41_r = "/fragment@77/__overlay__/cs35l41@41";
	};

	__fixups__ {
		pinctrl_4 = "/fragment@0:target:0\0/fragment@5:target:0\0/fragment@9:target:0\0/fragment@30:target:0\0/fragment@58:target:0\0/fragment@67:target:0\0/fragment@75:target:0";
		pinctrl_1 = "/fragment@1:target:0\0/fragment@8:target:0\0/fragment@10:target:0\0/fragment@18:target:0\0/fragment@44:target:0\0/fragment@57:target:0\0/fragment@60:target:0\0/fragment@62:target:0\0/fragment@74:target:0";
		serial_16 = "/fragment@2:target:0";
		odm = "/fragment@3:target:0\0/fragment@36:target:0";
		gpp16 = "/fragment@3/__overlay__/btbcm:shutdown-gpios:0\0/fragment@35/__overlay__:gpios:0\0/fragment@35/__overlay__:gpios:12\0/fragment@77/__overlay__/cs35l41@40:reset-gpios:0";
		gpa6 = "/fragment@3/__overlay__/btbcm:host-wakeup-gpios:0\0/fragment@36/__overlay__/goodixfp:interrupt-parent:0\0/fragment@36/__overlay__/goodixfp:fp-gpio-irq:0\0/fragment@56/__overlay__/bcm4775@0:host-req-gpios:0\0/fragment@77/__overlay__/cs35l41@40:interrupt-parent:0";
		gpp14 = "/fragment@3/__overlay__/btbcm:device-wakeup-gpios:0\0/fragment@12/__overlay__/wlan:wl_reg_on:0\0/fragment@26/__overlay__:pcie,wlan-gpio:0";
		spi_5 = "/fragment@4:target:0\0/fragment@56:target:0";
		spi5_bus = "/fragment@4/__overlay__:pinctrl-0:0";
		spi5_cs_func = "/fragment@4/__overlay__:pinctrl-0:4";
		gpp1 = "/fragment@4/__overlay__/bcm4775@0:mcu-req-gpios:0";
		gpp0 = "/fragment@4/__overlay__/bcm4775@0:nstandby-gpios:0\0/fragment@56/__overlay__/bcm4775@0:mcu-resp-gpios:0";
		hsi2c_12 = "/fragment@6:target:0\0/fragment@61:target:0";
		gpa8 = "/fragment@6/__overlay__/fusb307b@50:interrupt-parent:0\0/fragment@6/__overlay__/fusb307b@50:usbpd,usbpd_int:0\0/fragment@6/__overlay__/max77759tcpc@25:interrupt-parent:0\0/fragment@6/__overlay__/max77759tcpc@25:usbpd,usbpd_int:0\0/fragment@20/__overlay__/button@2:gpios:0\0/fragment@modemif/__overlay__/cpif:gpio_cp2ap_wake_up:0\0/fragment@modemif/__overlay__/cpif:gpio_cp2ap_phone_active:0\0/fragment@50/__overlay__/st21nfc@08:interrupt-parent:0\0/fragment@50/__overlay__/st21nfc@08:irq-gpios:0\0/fragment@61/__overlay__/max77729pmic@0x66:max777x9,irq-gpio:0\0/fragment@61/__overlay__/max77759chrg@0x69:interrupt-parent:0\0/fragment@61/__overlay__/max77759chrg@0x69:max77759,irq-gpio:0";
		hsi2c12_bus = "/fragment@7:target:0\0/fragment@38:target:0";
		pinctrl_7 = "/fragment@11:target:0";
		pcie_1 = "/fragment@12:target:0\0/fragment@26:target:0\0/fragment@51:target:0";
		pcie1_clkreq = "/fragment@12/__overlay__:pinctrl-0:0";
		pcie1_perst = "/fragment@12/__overlay__:pinctrl-0:4";
		gpa7 = "/fragment@12/__overlay__/wlan:wl_host_wake:0\0/fragment@20/__overlay__/button@1:gpios:0";
		gph2 = "/fragment@12/__overlay__/wlan:wl_dev_wake:0";
		pinctrl_0 = "/fragment@13:target:0\0/fragment@19:target:0\0/fragment@43:target:0\0/fragment@52:target:0\0/fragment@59:target:0\0/fragment@66:target:0\0/fragment@73:target:0";
		acpm_mfd_bus0 = "/fragment@14:target:0";
		gpa0 = "/fragment@14/__overlay__/s2mpg10mfd@00:s2mpg10,irq-gpio:0\0/fragment@14/__overlay__/s2mpg10mfd@00:interrupt-parent:0\0/fragment@15/__overlay__/s2mpg11mfd@00:s2mpg11,irq-gpio:0\0/fragment@15/__overlay__/s2mpg11mfd@00:interrupt-parent:0";
		gpa5 = "/fragment@14/__overlay__/s2mpg10mfd@00:gpios:0\0/fragment@14/__overlay__/s2mpg10mfd@00:gpios:12\0/fragment@14/__overlay__/s2mpg10mfd@00:gpios:24\0/fragment@14/__overlay__/s2mpg10mfd@00:gpios:36\0/fragment@14/__overlay__/s2mpg10mfd@00:gpios:48\0/fragment@battery/__overlay__/google,mitigation:gpios:0\0/fragment@battery/__overlay__/google,mitigation:gpios:12";
		gpp19 = "/fragment@14/__overlay__/s2mpg10mfd@00:gpios:60\0/fragment@14/__overlay__/s2mpg10mfd@00:gpios:72\0/fragment@15/__overlay__/s2mpg11mfd@00:gpios:0\0/fragment@15/__overlay__/s2mpg11mfd@00:gpios:12";
		acpm_mfd_bus1 = "/fragment@15:target:0\0/fragment@63:target:0";
		acpm_mbox_test = "/fragment@16:target:0";
		serial_0 = "/fragment@17:target:0";
		gpio_keys = "/fragment@20:target:0";
		gpa10 = "/fragment@20/__overlay__/button@3:gpios:0";
		udc = "/fragment@21:target:0";
		usbdrd_phy0 = "/fragment@22:target:0\0/fragment@23:target:0";
		sub_pd_hsi0 = "/fragment@24:target:0";
		pcie_0 = "/fragment@25:target:0";
		aoc = "/fragment@27:target:0\0/fragment@28:target:0\0/fragment@78:target:0";
		hsi2c_7 = "/fragment@29:target:0\0/fragment@50:target:0";
		pinctrl_5 = "/fragment@31:target:0\0/fragment@48:target:0\0/fragment@53:target:0\0/fragment@68:target:0\0/fragment@76:target:0";
		hsi2c_2 = "/fragment@32:target:0\0/fragment@lwiscamera/__overlay__/sensor@2:i2c-bus:0\0/fragment@lwiscamera/__overlay__/eeprom@2:i2c-bus:0";
		gpp4 = "/fragment@32/__overlay__:gpios:0\0/fragment@32/__overlay__:gpios:12\0/fragment@lwiscamera/__overlay__/sensor@2:reset-gpios:0\0/fragment@lwiscamera/__overlay__/eeprom@2:reset-gpios:0\0/fragment@36/__overlay__/goodixfp:fp-gpio-reset:0";
		hsi2c_3 = "/fragment@33:target:0\0/fragment@lwiscamera/__overlay__/sensor@0:i2c-bus:0\0/fragment@lwiscamera/__overlay__/actuator@0:i2c-bus:0\0/fragment@lwiscamera/__overlay__/eeprom@0:i2c-bus:0";
		gpp6 = "/fragment@33/__overlay__:gpios:0\0/fragment@33/__overlay__:gpios:12\0/fragment@lwiscamera/__overlay__/sensor@0:reset-gpios:0\0/fragment@lwiscamera/__overlay__/sensor@1:reset-gpios:0\0/fragment@lwiscamera/__overlay__/eeprom@0:reset-gpios:0\0/fragment@lwiscamera/__overlay__/eeprom@1:reset-gpios:0";
		hsi2c_4 = "/fragment@34:target:0\0/fragment@lwiscamera/__overlay__/sensor@1:i2c-bus:0\0/fragment@lwiscamera/__overlay__/eeprom@1:i2c-bus:0";
		gpp8 = "/fragment@34/__overlay__:gpios:0\0/fragment@34/__overlay__:gpios:12";
		hsi2c_8 = "/fragment@35:target:0\0/fragment@lwiscamera/__overlay__/flash@0:i2c-bus:0\0/fragment@37:target:0\0/fragment@69:target:0\0/fragment@77:target:0";
		hsi2c8_bus = "/fragment@35/__overlay__:pinctrl-0:0\0/fragment@35/__overlay__:pinctrl-1:0\0/fragment@35/__overlay__:pinctrl-2:0\0/fragment@37/__overlay__:pinctrl-0:0\0/fragment@77/__overlay__:pinctrl-0:0";
		clock = "/fragment@lwiscamera/__overlay__/sensor@0:clocks:0\0/fragment@lwiscamera/__overlay__/sensor@0:clocks:8\0/fragment@lwiscamera/__overlay__/sensor@2:clocks:0\0/fragment@lwiscamera/__overlay__/sensor@2:clocks:8\0/fragment@lwiscamera/__overlay__/sensor@1:clocks:0\0/fragment@lwiscamera/__overlay__/sensor@1:clocks:8\0/fragment@lwiscamera/__overlay__/actuator@0:clocks:0\0/fragment@lwiscamera/__overlay__/actuator@0:clocks:8\0/fragment@lwiscamera/__overlay__/eeprom@0:clocks:0\0/fragment@lwiscamera/__overlay__/eeprom@0:clocks:8\0/fragment@lwiscamera/__overlay__/eeprom@1:clocks:0\0/fragment@lwiscamera/__overlay__/eeprom@1:clocks:8\0/fragment@lwiscamera/__overlay__/eeprom@2:clocks:0\0/fragment@lwiscamera/__overlay__/eeprom@2:clocks:8\0/fragment@50/__overlay__/st21nfc@08:clocks:0";
		sensor_mclk1_fn = "/fragment@lwiscamera/__overlay__/sensor@0:pinctrl-0:0";
		sensor_mclk1_out = "/fragment@lwiscamera/__overlay__/sensor@0:pinctrl-1:0";
		sensor_mclk2_fn = "/fragment@lwiscamera/__overlay__/sensor@2:pinctrl-0:0";
		sensor_mclk2_out = "/fragment@lwiscamera/__overlay__/sensor@2:pinctrl-1:0";
		sensor_mclk3_fn = "/fragment@lwiscamera/__overlay__/sensor@1:pinctrl-0:0";
		sensor_mclk3_out = "/fragment@lwiscamera/__overlay__/sensor@1:pinctrl-1:0";
		gpp27 = "/fragment@lwiscamera/__overlay__/flash@0:enable-gpios:0\0/fragment@lwiscamera/__overlay__/flash@0:enable-gpios:12\0/fragment@lwiscamera/__overlay__/flash@0:enable-gpios:24\0/fragment@61/__overlay__/max77759chrg@0x69:max77759,bst-sel:0";
		s2mpu_hsi1 = "/fragment@modemif/__overlay__/cpif:s2mpu:0";
		gph0 = "/fragment@modemif/__overlay__/cpif:gpio_ap2cp_wake_up:0\0/fragment@modemif/__overlay__/cpif:gpio_ap2cp_dump_noti:0";
		gph1 = "/fragment@modemif/__overlay__/cpif:gpio_ap2cp_cp_pwr_on:0\0/fragment@modemif/__overlay__/cpif:gpio_ap2cp_pda_active:0\0/fragment@modemif/__overlay__/cpif:gpio_ap2cp_nreset_n:0";
		gpa9 = "/fragment@modemif/__overlay__/cpif:gpio_cp2ap_cp_ps_hold:0\0/fragment@54/__overlay__/touchscreen@0:sec,irq_gpio:0\0/fragment@55/__overlay__/gsa_gsc@0:interrupt-parent:0\0/fragment@55/__overlay__/gsa_gsc@0:gsc,ctdl_ap_irq:0\0/fragment@61/__overlay__/max77759fg@0x36:maxim,irq-gpio:0\0/fragment@69/__overlay__/p9412@3c:idt,irq_gpio:0\0/fragment@77/__overlay__/cs35l41@41:interrupt-parent:0";
		cp_rmem = "/fragment@modemif/__overlay__/cp_shmem:memory-region:0";
		cp_msi_rmem = "/fragment@modemif/__overlay__/cp_shmem:memory-region:4";
		cp_rmem_1 = "/fragment@modemif/__overlay__/cp_shmem:memory-region:8";
		cp_rmem_2 = "/fragment@modemif/__overlay__/cp_shmem:memory-region:12";
		spi9_cs_func = "/fragment@39:target:0\0/fragment@40/__overlay__:pinctrl-0:4";
		spi_9 = "/fragment@40:target:0";
		spi9_bus = "/fragment@40/__overlay__:pinctrl-0:0";
		cp_tm1 = "/fragment@41:target:0\0/fragment@42/__overlay__/cp_on_chip_0:thermal-sensors:0\0/fragment@42/__overlay__/cp_on_chip_1:thermal-sensors:0\0/fragment@42/__overlay__/cp_on_chip_2:thermal-sensors:0\0/fragment@42/__overlay__/cp_on_chip_3:thermal-sensors:0\0/fragment@42/__overlay__/cp_on_chip_4:thermal-sensors:0\0/fragment@42/__overlay__/cp_on_chip_5:thermal-sensors:0\0/fragment@42/__overlay__/cp_on_chip_6:thermal-sensors:0\0/fragment@42/__overlay__/rf2_therm:thermal-sensors:0\0/fragment@42/__overlay__/rf1_therm:thermal-sensors:0";
		thermal_zones = "/fragment@42:target:0\0/fragment@64:target:0\0/fragment@65:target:0";
		pinctrl_6 = "/fragment@45:target:0";
		drmdsim0 = "/fragment@46:target:0";
		gpp24 = "/fragment@46/__overlay__/panel@0:reset-gpios:0\0/fragment@46/__overlay__/panel@1:reset-gpios:0\0/fragment@50/__overlay__/st21nfc@08:reset-gpios:0\0/fragment@77/__overlay__/drv2624_haptics@5a:ti,reset-gpio:0";
		drmdsim1 = "/fragment@47:target:0";
		hsi2c7_bus = "/fragment@49:target:0";
		gpp26 = "/fragment@50/__overlay__/st21nfc@08:clkreq-gpios:0\0/fragment@50/__overlay__/st21nfc@08:pidle-gpios:0\0/fragment@54/__overlay__/touchscreen@0:sec,switch_gpio:0\0/fragment@54/__overlay__/touchscreen@0:sec,reset_gpio:0";
		spi_11 = "/fragment@54:target:0";
		gsa = "/fragment@55:target:0";
		cpufreq_domain0 = "/fragment@64/__overlay__/disp_therm/cooling-maps/cpu0-map:cooling-device:0";
		cpufreq_domain1 = "/fragment@64/__overlay__/disp_therm/cooling-maps/cpu1-map:cooling-device:0";
		cpufreq_domain2 = "/fragment@64/__overlay__/disp_therm/cooling-maps/cpu2-map:cooling-device:0";
		mali = "/fragment@64/__overlay__/disp_therm/cooling-maps/gpu-map:cooling-device:0";
		dai_be_tdm0_rx = "/fragment@70:target:0";
		dai_be_tdm0_tx = "/fragment@71:target:0";
		aoc_snd_card = "/fragment@72:target:0";
		V_SYS_dummy = "/fragment@77/__overlay__/cs35l41@40:VP-supply:0\0/fragment@77/__overlay__/cs35l41@41:VP-supply:0";
		gpp23 = "/fragment@77/__overlay__/cs35l41@41:reset-gpios:0";
	};

	__local_fixups__ {

		fragment@3 {

			__overlay__ {

				btbcm {
					pinctrl-0 = <0x00 0x04 0x08>;
				};
			};
		};

		fragment@4 {

			__overlay__ {

				bcm4775@0 {
					pinctrl-0 = <0x00 0x04 0x08 0x0c>;
				};
			};
		};

		fragment@6 {

			__overlay__ {

				fusb307b@50 {
					pinctrl-0 = <0x00>;
					ls = <0x00>;
					conn = <0x00>;

					connector {

						port {

							endpoint@0 {
								remote-endpoint = <0x00>;
							};
						};
					};

					port {

						endpoint@0 {
							remote-endpoint = <0x00>;
						};
					};
				};

				max20339ovp@35 {
					max20339,irq-gpio = <0x00>;
				};

				max77759tcpc@25 {
					pinctrl-0 = <0x00>;
					in-switch-gpio = <0x00>;
					max20339,ovp = <0x00>;
					conn = <0x00>;

					connector {

						port {

							endpoint@0 {
								remote-endpoint = <0x00>;
							};
						};
					};

					port {

						endpoint@0 {
							remote-endpoint = <0x00>;
						};
					};
				};
			};
		};

		fragment@typec {

			__overlay__ {

				google,usbc_port_cooling_dev {
					extcon = <0x00>;
				};
			};
		};

		fragment@12 {

			__overlay__ {
				pinctrl-0 = <0x08 0x0c 0x10>;
			};
		};

		fragment@14 {

			__overlay__ {

				s2mpg10mfd@00 {
					pinctrl-0 = <0x00 0x04>;

					s2mpg10_gpio {
						gpio-ranges = <0x00>;
					};
				};
			};
		};

		fragment@15 {

			__overlay__ {

				s2mpg11mfd@00 {
					pinctrl-0 = <0x00>;

					s2mpg11_gpio {
						gpio-ranges = <0x00>;
					};
				};
			};
		};

		fragment@16 {

			__overlay__ {
				main-pmic = <0x00>;
				sub-pmic = <0x00>;
			};
		};

		fragment@20 {

			__overlay__ {
				pinctrl-0 = <0x00 0x04 0x08>;
			};
		};

		fragment@21 {

			__overlay__ {
				extcon = <0x00>;
			};
		};

		fragment@23 {

			__overlay__ {
				hs_tune_param = <0x00>;
				ss_tune_param = <0x00>;
				extcon = <0x00>;
			};
		};

		fragment@24 {

			__overlay__ {
				vdd_hsi-supply = <0x00>;
				vdd085-supply = <0x00>;
				vdd18-supply = <0x00>;
				vdd30-supply = <0x00>;
			};
		};

		fragment@25 {

			__overlay__ {
				vreg1-supply = <0x00>;
				vreg2-supply = <0x00>;
			};
		};

		fragment@26 {

			__overlay__ {
				vreg1-supply = <0x00>;
				vreg2-supply = <0x00>;
			};
		};

		fragment@27 {

			__overlay__ {
				sensor_1v8-supply = <0x00>;
				sensor_3v3-supply = <0x00>;
			};
		};

		fragment@28 {

			__overlay__ {
				sensor_1v8-supply = <0x00>;
				sensor_3v3-supply = <0x00>;
			};
		};

		fragment@29 {

			__overlay__ {

				slg51000@75 {
					dlg,cs-gpios = <0x00>;
				};
			};
		};

		fragment@32 {

			__overlay__ {
				pinctrl-0 = <0x00>;
				pinctrl-1 = <0x00>;
				pinctrl-2 = <0x00>;
			};
		};

		fragment@33 {

			__overlay__ {
				pinctrl-0 = <0x00>;
				pinctrl-1 = <0x00>;
				pinctrl-2 = <0x00>;
			};
		};

		fragment@34 {

			__overlay__ {
				pinctrl-0 = <0x00>;
				pinctrl-1 = <0x00>;
				pinctrl-2 = <0x00>;
			};
		};

		fragment@lwiscamera {

			__overlay__ {

				sensor@0 {
					enable-gpios = <0x00>;
					regulators = <0x00 0x04 0x08 0x0c 0x10>;
				};

				sensor@2 {
					enable-gpios = <0x00>;
					regulators = <0x00>;
				};

				sensor@1 {
					enable-gpios = <0x00>;
					regulators = <0x00 0x04 0x08 0x0c>;
				};

				actuator@0 {
					enable-gpios = <0x00>;
					regulators = <0x00 0x04>;
				};

				eeprom@0 {
					enable-gpios = <0x00 0x0c>;
					regulators = <0x00>;
				};

				eeprom@1 {
					enable-gpios = <0x00>;
					regulators = <0x00 0x04 0x08 0x0c>;
				};

				eeprom@2 {
					enable-gpios = <0x00>;
					regulators = <0x00>;
				};

				flash@0 {
					pinctrl-0 = <0x00>;
					pinctrl-1 = <0x00>;
				};
			};
		};

		fragment@battery {

			__overlay__ {

				google_bms {
					nvmem = <0x00>;
				};

				google,mitigation {
					google,charger = <0x00>;
					google,power-supply = <0x00>;
					google,main-power = <0x00>;
					google,sub-power = <0x00>;
				};
			};
		};

		fragment@modemif {

			__overlay__ {

				cpif {
					pinctrl-0 = <0x00 0x04 0x08 0x0c 0x10 0x14 0x18 0x1c>;
				};
			};
		};

		fragment@46 {

			__overlay__ {

				panel@0 {
					touch = <0x00>;
					vci-supply = <0x00>;
					vddi-supply = <0x00>;
				};
			};
		};

		fragment@50 {

			__overlay__ {

				st21nfc@08 {
					pinctrl-0 = <0x00 0x04>;
				};
			};
		};

		fragment@54 {

			__overlay__ {
				pinctrl-0 = <0x00 0x04>;

				touchscreen@0 {
					pinctrl-0 = <0x00 0x04 0x08>;
					vdd-supply = <0x00>;
					avdd-supply = <0x00>;
				};
			};
		};

		fragment@61 {

			__overlay__ {

				max77729pmic@0x66 {
					pinctrl-0 = <0x00>;
					max77759,max_m5 = <0x00>;
					max20339,ovp = <0x00>;
				};

				max77759fg@0x36 {
					pinctrl-0 = <0x00>;
				};

				max77759chrg@0x69 {
					max77759,max_m5 = <0x00>;
					max77759,pmic = <0x00>;
					max77759,bst-on = <0x00>;
					max77759,extbst-ctl = <0x00>;
					max77759,lsw1-is_open = <0x00>;
					max77759,lsw1-is_closed = <0x00>;
					max77759,vin-is_valid = <0x00>;
				};
			};
		};

		fragment@64 {

			__overlay__ {

				soc_therm {
					thermal-sensors = <0x00>;
				};

				quiet_therm {
					thermal-sensors = <0x00>;
				};

				qi_therm {
					thermal-sensors = <0x00>;
				};

				therm_3 {
					thermal-sensors = <0x00>;
				};

				therm_4 {
					thermal-sensors = <0x00>;
				};

				disp_therm {
					thermal-sensors = <0x00>;

					cooling-maps {

						cpu0-map {
							trip = <0x00>;
						};

						cpu1-map {
							trip = <0x00>;
						};

						cpu2-map {
							trip = <0x00>;
						};

						gpu-map {
							trip = <0x00>;
						};
					};
				};

				ufs_stb_therm {
					thermal-sensors = <0x00>;
				};

				gnss_tcxo_therm {
					thermal-sensors = <0x00>;
				};
			};
		};

		fragment@65 {

			__overlay__ {

				soc {
					thermal-sensors = <0x00>;
				};

				vdroop1 {
					thermal-sensors = <0x00>;
				};

				vdroop2 {
					thermal-sensors = <0x00>;
				};

				batoilo {
					thermal-sensors = <0x00>;
				};

				pmic_120c {
					thermal-sensors = <0x00>;
				};

				pmic_140c {
					thermal-sensors = <0x00>;
				};

				pmic_overheat {
					thermal-sensors = <0x00>;
				};

				battery_cycle {
					thermal-sensors = <0x00>;
				};

				smpl_gm {
					thermal-sensors = <0x00>;
				};

				ocp_cpu1 {
					thermal-sensors = <0x00>;
				};

				ocp_cpu2 {
					thermal-sensors = <0x00>;
				};

				soft_ocp_cpu1 {
					thermal-sensors = <0x00>;
				};

				soft_ocp_cpu2 {
					thermal-sensors = <0x00>;
				};

				ocp_tpu {
					thermal-sensors = <0x00>;
				};

				soft_ocp_tpu {
					thermal-sensors = <0x00>;
				};

				ocp_gpu {
					thermal-sensors = <0x00>;
				};

				soft_ocp_gpu {
					thermal-sensors = <0x00>;
				};
			};
		};

		fragment@69 {

			__overlay__ {

				p9412@3c {
					pinctrl-0 = <0x00 0x04 0x08>;
				};
			};
		};

		fragment@70 {

			__overlay__ {

				codec {
					sound-dai = <0x00 0x08>;
				};
			};
		};

		fragment@71 {

			__overlay__ {

				codec {
					sound-dai = <0x00 0x08>;
				};
			};
		};

		fragment@72 {

			__overlay__ {

				clks {

					sys {

						sys@cs35l41_l {
							comp = <0x00>;
						};

						sys@cs35l41_r {
							comp = <0x00>;
						};
					};
				};
			};
		};

		fragment@77 {

			__overlay__ {

				drv2624_haptics@5a {
					pinctrl-0 = <0x00>;
				};

				cs35l41@40 {
					pinctrl-0 = <0x00 0x04>;
					VA-supply = <0x00>;
				};

				cs35l41@41 {
					pinctrl-0 = <0x00 0x04>;
					VA-supply = <0x00>;
				};
			};
		};
	};
};
